VERSION "1.0.x-173216:1"

NS_ :

BS_:

BU_: PropulsionBatteryCharger iBooster TCM HCU STEERING_CONTROLLER BMS Traction_Motor_Controller

BO_ 2565865739 EBC1_11: 8 Vector__XXX
 SG_ ABSActive : 4|2@1+ (1,0) [0|3] "" Vector__XXX
 SG_ ASREngineCtrlActive : 0|2@1+ (1,0) [0|3] "" Vector__XXX
 SG_ ASRBrakeCtrlActive : 2|2@1+ (1,0) [0|3] "" Vector__XXX
 SG_ BrakePedalPosition : 8|8@1+ (0.4,0) [0|100] "%" Vector__XXX
 SG_ ABSOffroadSwitch : 16|2@1+ (1,0) [0|3] "" Vector__XXX
 SG_ ASROffroadSwitch : 18|2@1+ (1,0) [0|3] "" Vector__XXX
 SG_ ASRHillHolderSwitch : 20|2@1+ (1,0) [0|3] "" Vector__XXX
 SG_ EBSBrakeSwitch : 6|2@1+ (1,0) [0|3] "" Vector__XXX
 SG_ DL17_TractionCtrlOverrideSwitch : 22|2@1+ (1,0) [0|0] "" Vector__XXX
 SG_ AcceleratorInterlockSwitch : 24|2@1+ (1,0) [0|3] "" Vector__XXX
 SG_ EngineDerateSwitch : 26|2@1+ (1,0) [0|3] "" Vector__XXX
 SG_ AuxEngineShutdownSwitch : 28|2@1+ (1,0) [0|3] "" Vector__XXX
 SG_ RemoteAcceleratorSwitch : 30|2@1+ (1,0) [0|3] "" Vector__XXX
 SG_ EngineRetarderSelection : 32|8@1+ (0.4,0) [0|100] "%" Vector__XXX
 SG_ ABSFullyOperational : 40|2@1+ (1,0) [0|3] "" Vector__XXX
 SG_ EBSRedWarningState : 42|2@1+ (1,0) [0|3] "" Vector__XXX
 SG_ ABSEBSAmberWarningState : 44|2@1+ (1,0) [0|3] "" Vector__XXX
 SG_ SourceAddress : 48|8@1+ (1,0) [0|253] "" Vector__XXX
 SG_ ATC_ASR_InfoSig : 46|2@1+ (1,0) [0|3] "" Vector__XXX

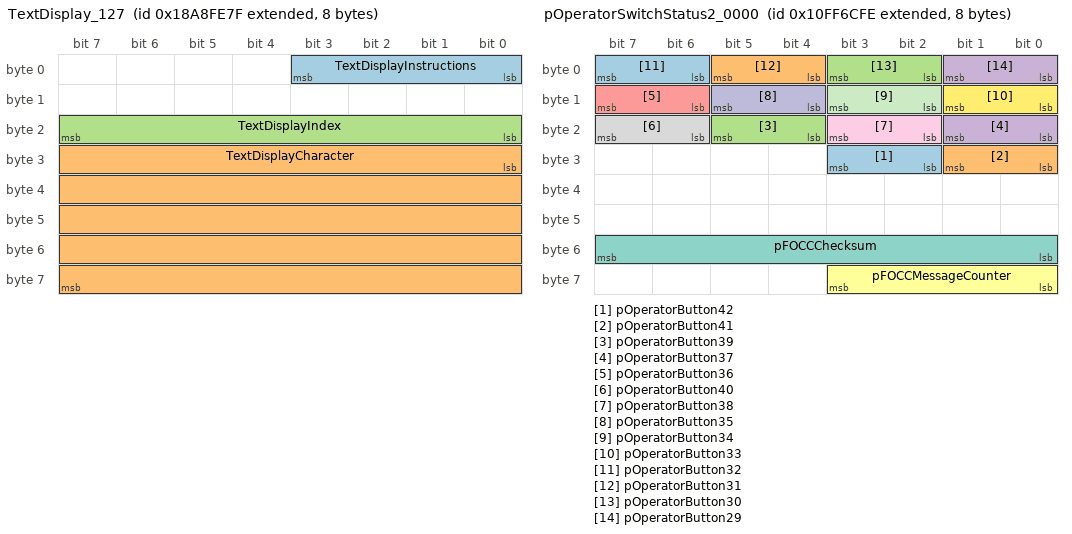
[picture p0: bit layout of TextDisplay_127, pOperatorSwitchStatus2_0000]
BO_ 2561212031 TextDisplay_127: 8 Vector__XXX
 SG_ TextDisplayInstructions : 0|4@1+ (1,0) [0|15] "" Vector__XXX
 SG_ TextDisplayCharacter : 24|40@1+ (1,0) [0|1099511627800] "ASCII" Vector__XXX
 SG_ TextDisplayIndex : 16|8@1+ (1,0) [0|250] "Count" Vector__XXX

BO_ 2432658686 pOperatorSwitchStatus2_0000: 8 Vector__XXX
 SG_ pOperatorButton42 : 26|2@1+ (1,0) [0|3] "" Vector__XXX
 SG_ pOperatorButton41 : 24|2@1+ (1,0) [0|3] "" Vector__XXX
 SG_ pOperatorButton39 : 20|2@1+ (1,0) [0|3] "" Vector__XXX
 SG_ pOperatorButton37 : 16|2@1+ (1,0) [0|3] "" Vector__XXX
 SG_ pOperatorButton36 : 14|2@1+ (1,0) [0|3] "" Vector__XXX
 SG_ pFOCCMessageCounter : 56|4@1+ (1,0) [0|15] "" Vector__XXX
 SG_ pFOCCChecksum : 48|8@1+ (1,0) [0|255] "" Vector__XXX
 SG_ pOperatorButton40 : 22|2@1+ (1,0) [0|3] "" Vector__XXX
 SG_ pOperatorButton38 : 18|2@1+ (1,0) [0|3] "" Vector__XXX
 SG_ pOperatorButton35 : 12|2@1+ (1,0) [0|3] "" Vector__XXX
 SG_ pOperatorButton34 : 10|2@1+ (1,0) [0|3] "" Vector__XXX
 SG_ pOperatorButton33 : 8|2@1+ (1,0) [0|3] "" Vector__XXX
 SG_ pOperatorButton32 : 6|2@1+ (1,0) [0|3] "" Vector__XXX
 SG_ pOperatorButton31 : 4|2@1+ (1,0) [0|3] "" Vector__XXX
 SG_ pOperatorButton30 : 2|2@1+ (1,0) [0|3] "" Vector__XXX
 SG_ pOperatorButton29 : 0|2@1+ (1,0) [0|3] "" Vector__XXX

BO_ 2633984766 pDriveSystemStatus_0: 8 Vector__XXX
 SG_ pHeatedGripEnable : 48|2@1+ (1,0) [0|3] "" Vector__XXX
 SG_ pSideStandStatus : 36|2@1+ (1,0) [0|3] "" Vector__XXX
 SG_ pTetherSwitchStatus : 46|2@1+ (1,0) [0|3] "" Vector__XXX
 SG_ pLowFuelIndicatorStatus : 10|2@1+ (1,0) [0|3] "" Vector__XXX
 SG_ pOperatorNotInOperatingStation : 38|2@1+ (1,0) [0|3] "" Vector__XXX
 SG_ pParkBrakeIndicatorStatus : 40|3@1+ (1,0) [0|7] "" Vector__XXX
 SG_ pADCRequested : 34|2@1+ (1,0) [0|3] "" Vector__XXX
 SG_ pAWDModeRequested : 32|2@1+ (1,0) [0|3] "" Vector__XXX
 SG_ pRWDModeRequested : 30|2@1+ (1,0) [0|3] "" Vector__XXX
 SG_ pTurfModeRequested : 28|2@1+ (1,0) [0|3] "" Vector__XXX
 SG_ pADCStatus : 0|2@1+ (1,0) [0|3] "" Vector__XXX
 SG_ pTreadleNeutralStatus : 2|2@1+ (1,0) [0|3] "" Vector__XXX
 SG_ pTreadleReverseStatus : 4|2@1+ (1,0) [0|3] "" Vector__XXX
 SG_ pSecurityLightStatus : 6|2@1+ (1,0) [0|3] "" Vector__XXX
 SG_ pHighBeamIndicatorStatus : 8|2@1+ (1,0) [0|3] "" Vector__XXX
 SG_ pHeatedGripsPercentage : 16|8@1+ (0.4,0) [0|100] "%" Vector__XXX
 SG_ pCruiseControlSetStatus : 24|2@1+ (1,0) [0|3] "" Vector__XXX
 SG_ pSeatBeltIndicatorStatus : 12|3@1+ (1,0) [0|7] "" Vector__XXX

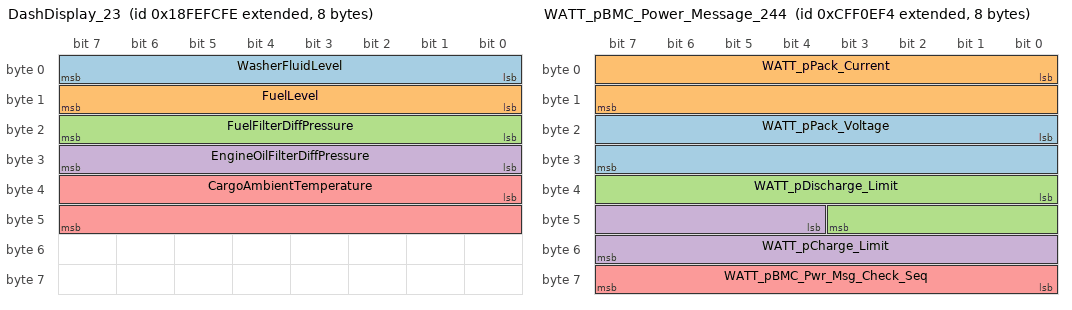
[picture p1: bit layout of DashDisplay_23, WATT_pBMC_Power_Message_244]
BO_ 2566847742 DashDisplay_23: 8 Vector__XXX
 SG_ WasherFluidLevel : 0|8@1+ (0.4,0) [0|100] "%" Vector__XXX
 SG_ FuelLevel : 8|8@1+ (0.4,0) [0|100] "%" Vector__XXX
 SG_ FuelFilterDiffPressure : 16|8@1+ (2,0) [0|500] "kPa" Vector__XXX
 SG_ EngineOilFilterDiffPressure : 24|8@1+ (0.5,0) [0|125] "kPa" Vector__XXX
 SG_ CargoAmbientTemperature : 32|16@1+ (0.03125,-273) [-273|1735] "°C" Vector__XXX

BO_ 2566832638 HiResVehicleDist_23: 8 Vector__XXX
 SG_ HighResolTotalVehicleDistance : 0|32@1+ (0.005,0) [0|21055406] "km" Vector__XXX
 SG_ HighResolTripDistance : 32|32@1+ (0.005,0) [0|21055406] "km" Vector__XXX

BO_ 2432656640 pOperatorSwitchStatus_0: 8 Vector__XXX
 SG_ pOperatorButton29 : 58|2@1+ (1,0) [0|3] "" Vector__XXX
 SG_ pOperatorButton1 : 0|2@1+ (1,0) [0|3] "" Vector__XXX
 SG_ pOperatorButton2 : 2|2@1+ (1,0) [0|3] "" Vector__XXX
 SG_ pOperatorButton3 : 4|2@1+ (1,0) [0|3] "" Vector__XXX
 SG_ pOperatorButton4 : 6|2@1+ (1,0) [0|3] "" Vector__XXX
 SG_ pOperatorButton5 : 8|2@1+ (1,0) [0|3] "" Vector__XXX
 SG_ pOperatorButton6 : 10|2@1+ (1,0) [0|3] "" Vector__XXX
 SG_ pOperatorButton7 : 12|2@1+ (1,0) [0|3] "" Vector__XXX
 SG_ pOperatorButton8 : 14|2@1+ (1,0) [0|3] "" Vector__XXX
 SG_ pOperatorButton9 : 16|2@1+ (1,0) [0|3] "" Vector__XXX
 SG_ pOperatorButton10 : 18|2@1+ (1,0) [0|3] "" Vector__XXX
 SG_ pOperatorButton11 : 20|2@1+ (1,0) [0|3] "" Vector__XXX
 SG_ pOperatorButton12 : 22|2@1+ (1,0) [0|3] "" Vector__XXX
 SG_ pOperatorButton13 : 24|2@1+ (1,0) [0|3] "" Vector__XXX
 SG_ pOperatorButton14 : 26|2@1+ (1,0) [0|3] "" Vector__XXX
 SG_ pOperatorButton15 : 28|2@1+ (1,0) [0|3] "" Vector__XXX
 SG_ pOperatorButton16 : 30|2@1+ (1,0) [0|3] "" Vector__XXX
 SG_ pOperatorButton17 : 32|2@1+ (1,0) [0|3] "" Vector__XXX
 SG_ pOperatorButton18 : 34|2@1+ (1,0) [0|3] "" Vector__XXX
 SG_ pOperatorButton19 : 36|2@1+ (1,0) [0|3] "" Vector__XXX
 SG_ pOperatorButton20 : 38|2@1+ (1,0) [0|3] "" Vector__XXX
 SG_ pOperatorButton21 : 40|2@1+ (1,0) [0|3] "" Vector__XXX
 SG_ pOperatorButton22 : 42|2@1+ (1,0) [0|3] "" Vector__XXX
 SG_ pOperatorButton23 : 44|2@1+ (1,0) [0|3] "" Vector__XXX
 SG_ pOperatorButton24 : 46|2@1+ (1,0) [0|3] "" Vector__XXX
 SG_ pOperatorButton25 : 48|2@1+ (1,0) [0|3] "" Vector__XXX
 SG_ pOperatorButton26 : 50|2@1+ (1,0) [0|3] "" Vector__XXX
 SG_ pOperatorButton27 : 52|2@1+ (1,0) [0|3] "" Vector__XXX
 SG_ pOperatorButton28 : 54|2@1+ (1,0) [0|3] "" Vector__XXX
 SG_ pSideStandStatus : 56|2@1+ (1,0) [0|3] "" Vector__XXX

BO_ 2566804212 VehicleElectricalPower3_244: 8 Vector__XXX
 SG_ NetBattCurrentHiRange : 16|16@1+ (0.05,0) [0|3276.75] "A" Vector__XXX

BO_ 2566804211 VehicleElectricalPower3_243: 8 BMS
 SG_ NetBattCurrentHiRange : 16|16@1+ (0.05,0) [0|3276.75] "A" Vector__XXX

BO_ 2365525748 WATT_pBMC_Power_Message_244: 8 Vector__XXX
 SG_ WATT_pPack_Voltage : 16|16@1+ (0.05,0) [0|3212.75] "V" Vector__XXX
 SG_ WATT_pPack_Current : 0|16@1+ (0.05,-1600) [-1600|1612.75] "A" Vector__XXX
 SG_ WATT_pDischarge_Limit : 32|12@1+ (0.5,0) [0|2007.5] "A" Vector__XXX
 SG_ WATT_pCharge_Limit : 44|12@1+ (0.5,0) [0|2007.5] "A" Vector__XXX
 SG_ WATT_pBMC_Pwr_Msg_Check_Seq : 56|8@1+ (1,0) [0|255] "" Vector__XXX

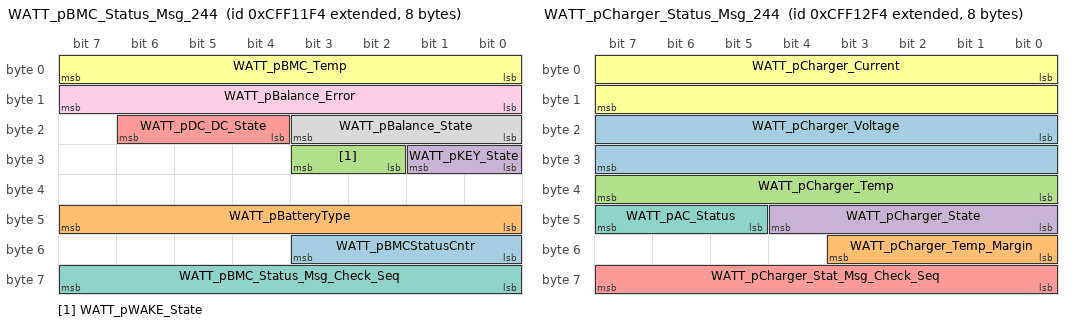
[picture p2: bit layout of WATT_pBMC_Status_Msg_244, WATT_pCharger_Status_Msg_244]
BO_ 2365526516 WATT_pBMC_Status_Msg_244: 8 Vector__XXX
 SG_ WATT_pBMCStatusCntr : 48|4@1+ (1,0) [0|15] "" Vector__XXX
 SG_ WATT_pBatteryType : 40|8@1+ (1,0) [0|255] "" Vector__XXX
 SG_ WATT_pWAKE_State : 26|2@1+ (1,0) [0|3] "" Vector__XXX
 SG_ WATT_pKEY_State : 24|2@1+ (1,0) [0|3] "" Vector__XXX
 SG_ WATT_pDC_DC_State : 20|3@1+ (1,0) [0|7] "" Vector__XXX
 SG_ WATT_pBMC_Temp : 0|8@1+ (1,-40) [-40|200] "C" Vector__XXX
 SG_ WATT_pBMC_Status_Msg_Check_Seq : 56|8@1+ (1,0) [0|255] "" Vector__XXX
 SG_ WATT_pBalance_State : 16|4@1+ (1,0) [0|15] "" Vector__XXX
 SG_ WATT_pBalance_Error : 8|8@1+ (0.5,-6.4) [-6.4|6.1] "%" Vector__XXX

BO_ 2365526772 WATT_pCharger_Status_Msg_244: 8 Vector__XXX
 SG_ WATT_pCharger_Voltage : 16|16@1+ (0.05,0) [0|3212.75] "V" Vector__XXX
 SG_ WATT_pCharger_Temp_Margin : 48|4@1+ (1,0) [0|15] "" Vector__XXX
 SG_ WATT_pCharger_Temp : 32|8@1+ (1,-40) [-40|200] "C" Vector__XXX
 SG_ WATT_pCharger_State : 40|5@1+ (1,0) [0|31] "" Vector__XXX
 SG_ WATT_pCharger_Stat_Msg_Check_Seq : 56|8@1+ (1,0) [0|255] "" Vector__XXX
 SG_ WATT_pCharger_Current : 0|16@1+ (0.05,-1600) [-1600|1612.75] "A" Vector__XXX
 SG_ WATT_pAC_Status : 45|3@1+ (1,0) [0|7] "" Vector__XXX

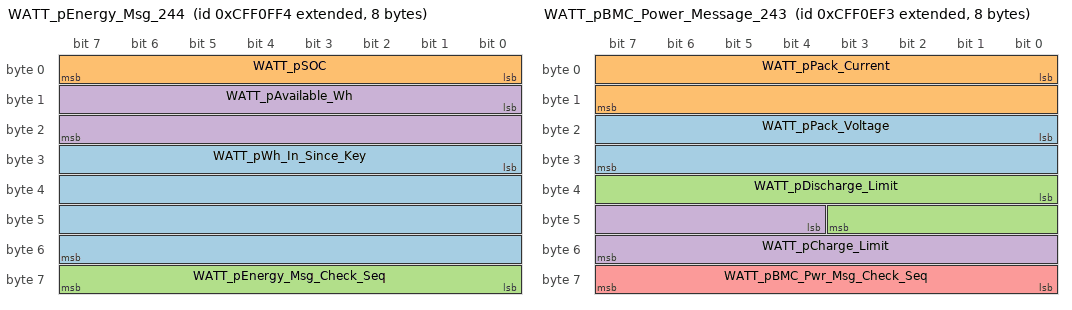
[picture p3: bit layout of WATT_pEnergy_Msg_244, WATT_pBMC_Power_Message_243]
BO_ 2365526004 WATT_pEnergy_Msg_244: 8 Vector__XXX
 SG_ WATT_pWh_In_Since_Key : 24|32@1+ (6.10352E-005,-131072) [-131072|126000] "Wh" Vector__XXX
 SG_ WATT_pSOC : 0|8@1+ (0.5,0) [0|100] "%" Vector__XXX
 SG_ WATT_pEnergy_Msg_Check_Seq : 56|8@1+ (1,0) [0|255] "" Vector__XXX
 SG_ WATT_pAvailable_Wh : 8|16@1+ (4,0) [0|257020] "Wh" Vector__XXX

BO_ 2365525747 WATT_pBMC_Power_Message_243: 8 BMS
 SG_ WATT_pPack_Voltage : 16|16@1+ (0.05,0) [0|3212.75] "V" Vector__XXX
 SG_ WATT_pPack_Current : 0|16@1+ (0.05,-1600) [-1600|1612.75] "A" Vector__XXX
 SG_ WATT_pDischarge_Limit : 32|12@1+ (0.5,0) [0|2007.5] "A" Vector__XXX
 SG_ WATT_pCharge_Limit : 44|12@1+ (0.5,0) [0|2007.5] "A" Vector__XXX
 SG_ WATT_pBMC_Pwr_Msg_Check_Seq : 56|8@1+ (1,0) [0|255] "" Vector__XXX

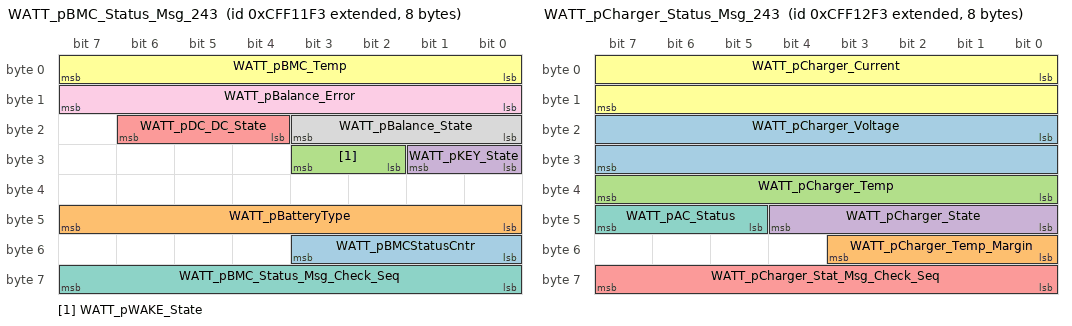
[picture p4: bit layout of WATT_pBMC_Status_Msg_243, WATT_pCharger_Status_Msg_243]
BO_ 2365526515 WATT_pBMC_Status_Msg_243: 8 BMS
 SG_ WATT_pBMCStatusCntr : 48|4@1+ (1,0) [0|15] "" Vector__XXX
 SG_ WATT_pBatteryType : 40|8@1+ (1,0) [0|255] "" Vector__XXX
 SG_ WATT_pWAKE_State : 26|2@1+ (1,0) [0|3] "" Vector__XXX
 SG_ WATT_pKEY_State : 24|2@1+ (1,0) [0|3] "" Vector__XXX
 SG_ WATT_pDC_DC_State : 20|3@1+ (1,0) [0|7] "" Vector__XXX
 SG_ WATT_pBMC_Temp : 0|8@1+ (1,-40) [-40|200] "C" Vector__XXX
 SG_ WATT_pBMC_Status_Msg_Check_Seq : 56|8@1+ (1,0) [0|255] "" Vector__XXX
 SG_ WATT_pBalance_State : 16|4@1+ (1,0) [0|15] "" Vector__XXX
 SG_ WATT_pBalance_Error : 8|8@1+ (0.5,-6.4) [-6.4|6.1] "%" Vector__XXX

BO_ 2365526771 WATT_pCharger_Status_Msg_243: 8 BMS
 SG_ WATT_pCharger_Voltage : 16|16@1+ (0.05,0) [0|3212.75] "V" Vector__XXX
 SG_ WATT_pCharger_Temp_Margin : 48|4@1+ (1,0) [0|15] "" Vector__XXX
 SG_ WATT_pCharger_Temp : 32|8@1+ (1,-40) [-40|200] "C" Vector__XXX
 SG_ WATT_pCharger_State : 40|5@1+ (1,0) [0|31] "" Vector__XXX
 SG_ WATT_pCharger_Stat_Msg_Check_Seq : 56|8@1+ (1,0) [0|255] "" Vector__XXX
 SG_ WATT_pCharger_Current : 0|16@1+ (0.05,-1600) [-1600|1612.75] "A" Vector__XXX
 SG_ WATT_pAC_Status : 45|3@1+ (1,0) [0|7] "" Vector__XXX

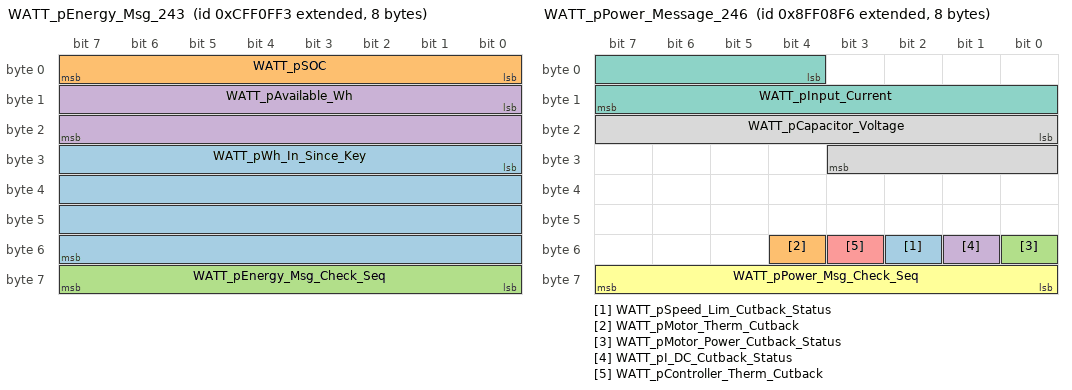
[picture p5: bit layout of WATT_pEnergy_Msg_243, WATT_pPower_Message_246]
BO_ 2365526003 WATT_pEnergy_Msg_243: 8 BMS
 SG_ WATT_pWh_In_Since_Key : 24|32@1+ (6.10352E-005,-131072) [-131072|126000] "Wh" Vector__XXX
 SG_ WATT_pSOC : 0|8@1+ (0.5,0) [0|100] "%" Vector__XXX
 SG_ WATT_pEnergy_Msg_Check_Seq : 56|8@1+ (1,0) [0|255] "" Vector__XXX
 SG_ WATT_pAvailable_Wh : 8|16@1+ (4,0) [0|257020] "Wh" Vector__XXX

BO_ 2298415094 WATT_pPerformance_Message_246: 8 Vector__XXX
 SG_ WATT_pUpper_Available_Torque : 16|8@1+ (2.5,-312.5) [-312.5|312.5] "Nm" Vector__XXX
 SG_ WATT_pPerformance_State : 0|4@1+ (1,0) [0|15] "" Vector__XXX
 SG_ WATT_pPerformance_Msg_Check_Seq : 56|8@1+ (1,0) [0|255] "" Vector__XXX
 SG_ WATT_pLower_Available_Torque : 28|8@1+ (2.5,-312.5) [-312.5|312.5] "Nm" Vector__XXX
 SG_ WATT_pActual_Motor_Velocity : 40|16@1+ (1,-32768) [-32768|31488] "RPM" Vector__XXX
 SG_ WATT_pActual_Motor_torque : 4|16@1+ (0.1,-3276.8) [-3276.8|3148.7] "Nm" Vector__XXX

BO_ 2298415350 WATT_pPower_Message_246: 8 Vector__XXX
 SG_ WATT_pSpeed_Lim_Cutback_Status : 50|1@1+ (1,0) [0|1] "" Vector__XXX
 SG_ WATT_pMotor_Therm_Cutback : 52|1@1+ (1,0) [0|1] "" Vector__XXX
 SG_ WATT_pMotor_Power_Cutback_Status : 48|1@1+ (1,0) [0|1] "" Vector__XXX
 SG_ WATT_pI_DC_Cutback_Status : 49|1@1+ (1,0) [0|1] "" Vector__XXX
 SG_ WATT_pController_Therm_Cutback : 51|1@1+ (1,0) [0|1] "" Vector__XXX
 SG_ WATT_pPower_Msg_Check_Seq : 56|8@1+ (1,0) [0|255] "" Vector__XXX
 SG_ WATT_pInput_Current : 4|12@1+ (1,0) [0|4095] "" Vector__XXX
 SG_ WATT_pCapacitor_Voltage : 16|12@1+ (1,0) [0|4095] "" Vector__XXX

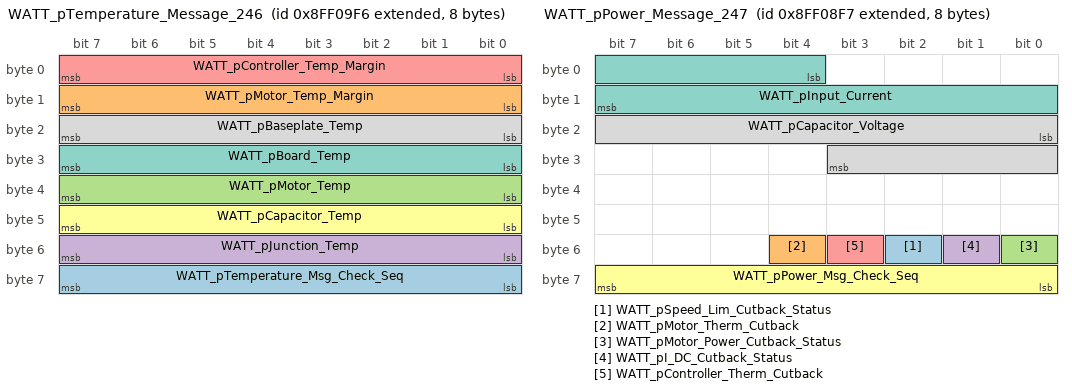
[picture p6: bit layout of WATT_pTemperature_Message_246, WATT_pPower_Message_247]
BO_ 2298415606 WATT_pTemperature_Message_246: 8 Vector__XXX
 SG_ WATT_pTemperature_Msg_Check_Seq : 56|8@1+ (1,0) [0|255] "" Vector__XXX
 SG_ WATT_pMotor_Temp_Margin : 8|8@1+ (1,0) [0|250] "C" Vector__XXX
 SG_ WATT_pMotor_Temp : 32|8@1+ (1,-40) [-40|210] "C" Vector__XXX
 SG_ WATT_pJunction_Temp : 48|8@1+ (1,-40) [-40|210] "C" Vector__XXX
 SG_ WATT_pController_Temp_Margin : 0|8@1+ (1,0) [0|250] "C" Vector__XXX
 SG_ WATT_pCapacitor_Temp : 40|8@1+ (1,-40) [-40|210] "C" Vector__XXX
 SG_ WATT_pBoard_Temp : 24|8@1+ (1,-40) [-40|210] "C" Vector__XXX
 SG_ WATT_pBaseplate_Temp : 16|8@1+ (1,-40) [-40|210] "C" Vector__XXX

BO_ 2298415095 WATT_pPerformance_Message_247: 8 Vector__XXX
 SG_ WATT_pUpper_Available_Torque : 16|8@1+ (2.5,-312.5) [-312.5|312.5] "Nm" Vector__XXX
 SG_ WATT_pPerformance_State : 0|4@1+ (1,0) [0|15] "" Vector__XXX
 SG_ WATT_pPerformance_Msg_Check_Seq : 56|8@1+ (1,0) [0|255] "" Vector__XXX
 SG_ WATT_pLower_Available_Torque : 28|8@1+ (2.5,-312.5) [-312.5|312.5] "Nm" Vector__XXX
 SG_ WATT_pActual_Motor_Velocity : 40|16@1+ (1,-32768) [-32768|31488] "RPM" Vector__XXX
 SG_ WATT_pActual_Motor_torque : 4|16@1+ (0.1,-3276.8) [-3276.8|3148.7] "Nm" Vector__XXX

BO_ 2298415351 WATT_pPower_Message_247: 8 Vector__XXX
 SG_ WATT_pSpeed_Lim_Cutback_Status : 50|1@1+ (1,0) [0|1] "" Vector__XXX
 SG_ WATT_pMotor_Therm_Cutback : 52|1@1+ (1,0) [0|1] "" Vector__XXX
 SG_ WATT_pMotor_Power_Cutback_Status : 48|1@1+ (1,0) [0|1] "" Vector__XXX
 SG_ WATT_pI_DC_Cutback_Status : 49|1@1+ (1,0) [0|1] "" Vector__XXX
 SG_ WATT_pController_Therm_Cutback : 51|1@1+ (1,0) [0|1] "" Vector__XXX
 SG_ WATT_pPower_Msg_Check_Seq : 56|8@1+ (1,0) [0|255] "" Vector__XXX
 SG_ WATT_pInput_Current : 4|12@1+ (1,0) [0|4095] "" Vector__XXX
 SG_ WATT_pCapacitor_Voltage : 16|12@1+ (1,0) [0|4095] "" Vector__XXX

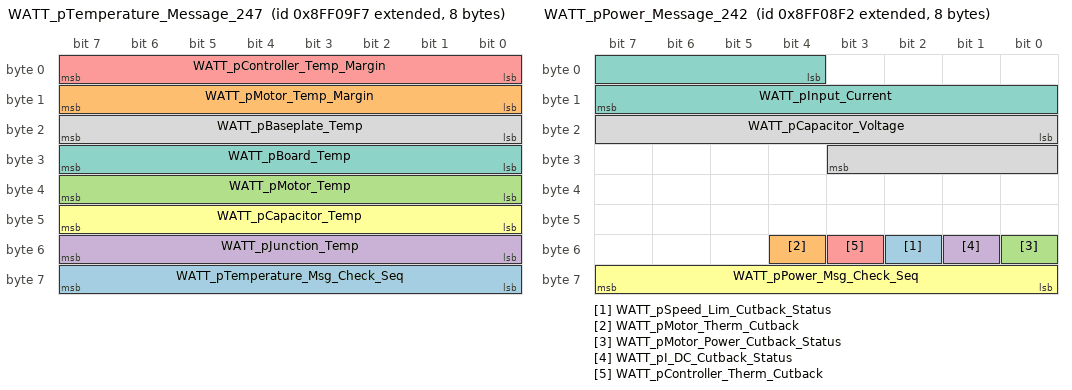
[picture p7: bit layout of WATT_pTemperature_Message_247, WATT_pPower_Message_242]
BO_ 2298415607 WATT_pTemperature_Message_247: 8 Vector__XXX
 SG_ WATT_pTemperature_Msg_Check_Seq : 56|8@1+ (1,0) [0|255] "" Vector__XXX
 SG_ WATT_pMotor_Temp_Margin : 8|8@1+ (1,0) [0|250] "C" Vector__XXX
 SG_ WATT_pMotor_Temp : 32|8@1+ (1,-40) [-40|210] "C" Vector__XXX
 SG_ WATT_pJunction_Temp : 48|8@1+ (1,-40) [-40|210] "C" Vector__XXX
 SG_ WATT_pController_Temp_Margin : 0|8@1+ (1,0) [0|250] "C" Vector__XXX
 SG_ WATT_pCapacitor_Temp : 40|8@1+ (1,-40) [-40|210] "C" Vector__XXX
 SG_ WATT_pBoard_Temp : 24|8@1+ (1,-40) [-40|210] "C" Vector__XXX
 SG_ WATT_pBaseplate_Temp : 16|8@1+ (1,-40) [-40|210] "C" Vector__XXX

BO_ 2298415090 WATT_pPerformance_Message_242: 8 Vector__XXX
 SG_ WATT_pUpper_Available_Torque : 16|8@1+ (2.5,-312.5) [-312.5|312.5] "Nm" Vector__XXX
 SG_ WATT_pPerformance_State : 0|4@1+ (1,0) [0|15] "" Vector__XXX
 SG_ WATT_pPerformance_Msg_Check_Seq : 56|8@1+ (1,0) [0|255] "" Vector__XXX
 SG_ WATT_pLower_Available_Torque : 28|8@1+ (2.5,-312.5) [-312.5|312.5] "Nm" Vector__XXX
 SG_ WATT_pActual_Motor_Velocity : 40|16@1+ (1,-32768) [-32768|31488] "RPM" Vector__XXX
 SG_ WATT_pActual_Motor_torque : 4|16@1+ (0.1,-3276.8) [-3276.8|3148.7] "Nm" Vector__XXX

BO_ 2298415346 WATT_pPower_Message_242: 8 Vector__XXX
 SG_ WATT_pSpeed_Lim_Cutback_Status : 50|1@1+ (1,0) [0|1] "" Vector__XXX
 SG_ WATT_pMotor_Therm_Cutback : 52|1@1+ (1,0) [0|1] "" Vector__XXX
 SG_ WATT_pMotor_Power_Cutback_Status : 48|1@1+ (1,0) [0|1] "" Vector__XXX
 SG_ WATT_pI_DC_Cutback_Status : 49|1@1+ (1,0) [0|1] "" Vector__XXX
 SG_ WATT_pController_Therm_Cutback : 51|1@1+ (1,0) [0|1] "" Vector__XXX
 SG_ WATT_pPower_Msg_Check_Seq : 56|8@1+ (1,0) [0|255] "" Vector__XXX
 SG_ WATT_pInput_Current : 4|12@1+ (1,0) [0|4095] "" Vector__XXX
 SG_ WATT_pCapacitor_Voltage : 16|12@1+ (1,0) [0|4095] "" Vector__XXX

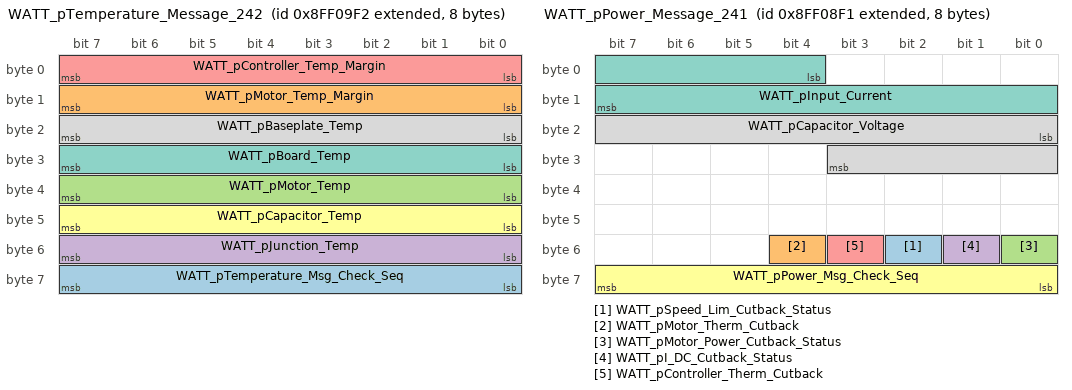
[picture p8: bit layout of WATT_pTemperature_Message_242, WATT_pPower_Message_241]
BO_ 2298415602 WATT_pTemperature_Message_242: 8 Vector__XXX
 SG_ WATT_pTemperature_Msg_Check_Seq : 56|8@1+ (1,0) [0|255] "" Vector__XXX
 SG_ WATT_pMotor_Temp_Margin : 8|8@1+ (1,0) [0|250] "C" Vector__XXX
 SG_ WATT_pMotor_Temp : 32|8@1+ (1,-40) [-40|210] "C" Vector__XXX
 SG_ WATT_pJunction_Temp : 48|8@1+ (1,-40) [-40|210] "C" Vector__XXX
 SG_ WATT_pController_Temp_Margin : 0|8@1+ (1,0) [0|250] "C" Vector__XXX
 SG_ WATT_pCapacitor_Temp : 40|8@1+ (1,-40) [-40|210] "C" Vector__XXX
 SG_ WATT_pBoard_Temp : 24|8@1+ (1,-40) [-40|210] "C" Vector__XXX
 SG_ WATT_pBaseplate_Temp : 16|8@1+ (1,-40) [-40|210] "C" Vector__XXX

BO_ 2298415089 WATT_pPerformance_Message_241: 8 Vector__XXX
 SG_ WATT_pUpper_Available_Torque : 16|8@1+ (2.5,-312.5) [-312.5|312.5] "Nm" Vector__XXX
 SG_ WATT_pPerformance_State : 0|4@1+ (1,0) [0|15] "" Vector__XXX
 SG_ WATT_pPerformance_Msg_Check_Seq : 56|8@1+ (1,0) [0|255] "" Vector__XXX
 SG_ WATT_pLower_Available_Torque : 28|8@1+ (2.5,-312.5) [-312.5|312.5] "Nm" Vector__XXX
 SG_ WATT_pActual_Motor_Velocity : 40|16@1+ (1,-32768) [-32768|31488] "RPM" Vector__XXX
 SG_ WATT_pActual_Motor_torque : 4|16@1+ (0.1,-3276.8) [-3276.8|3148.7] "Nm" Vector__XXX

BO_ 2298415345 WATT_pPower_Message_241: 8 Vector__XXX
 SG_ WATT_pSpeed_Lim_Cutback_Status : 50|1@1+ (1,0) [0|1] "" Vector__XXX
 SG_ WATT_pMotor_Therm_Cutback : 52|1@1+ (1,0) [0|1] "" Vector__XXX
 SG_ WATT_pMotor_Power_Cutback_Status : 48|1@1+ (1,0) [0|1] "" Vector__XXX
 SG_ WATT_pI_DC_Cutback_Status : 49|1@1+ (1,0) [0|1] "" Vector__XXX
 SG_ WATT_pController_Therm_Cutback : 51|1@1+ (1,0) [0|1] "" Vector__XXX
 SG_ WATT_pPower_Msg_Check_Seq : 56|8@1+ (1,0) [0|255] "" Vector__XXX
 SG_ WATT_pInput_Current : 4|12@1+ (1,0) [0|4095] "" Vector__XXX
 SG_ WATT_pCapacitor_Voltage : 16|12@1+ (1,0) [0|4095] "" Vector__XXX

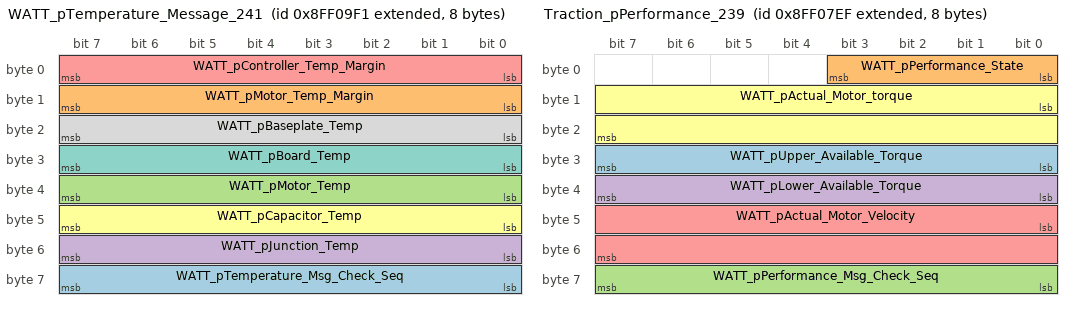
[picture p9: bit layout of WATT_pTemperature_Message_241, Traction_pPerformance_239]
BO_ 2298415601 WATT_pTemperature_Message_241: 8 Vector__XXX
 SG_ WATT_pTemperature_Msg_Check_Seq : 56|8@1+ (1,0) [0|255] "" Vector__XXX
 SG_ WATT_pMotor_Temp_Margin : 8|8@1+ (1,0) [0|250] "C" Vector__XXX
 SG_ WATT_pMotor_Temp : 32|8@1+ (1,-40) [-40|210] "C" Vector__XXX
 SG_ WATT_pJunction_Temp : 48|8@1+ (1,-40) [-40|210] "C" Vector__XXX
 SG_ WATT_pController_Temp_Margin : 0|8@1+ (1,0) [0|250] "C" Vector__XXX
 SG_ WATT_pCapacitor_Temp : 40|8@1+ (1,-40) [-40|210] "C" Vector__XXX
 SG_ WATT_pBoard_Temp : 24|8@1+ (1,-40) [-40|210] "C" Vector__XXX
 SG_ WATT_pBaseplate_Temp : 16|8@1+ (1,-40) [-40|210] "C" Vector__XXX

BO_ 2298415087 Traction_pPerformance_239: 8 Traction_Motor_Controller
 SG_ WATT_pUpper_Available_Torque : 24|8@1+ (2.5,-312.5) [-312.5|312.5] "Nm" Vector__XXX
 SG_ WATT_pPerformance_State : 0|4@1+ (1,0) [0|15] "" Vector__XXX
 SG_ WATT_pPerformance_Msg_Check_Seq : 56|8@1+ (1,0) [0|255] "" Vector__XXX
 SG_ WATT_pLower_Available_Torque : 32|8@1+ (2.5,-312.5) [-312.5|312.5] "Nm" Vector__XXX
 SG_ WATT_pActual_Motor_Velocity : 40|16@1+ (1,-32768) [-32768|31488] "RPM" Vector__XXX
 SG_ WATT_pActual_Motor_torque : 8|16@1+ (0.1,-3276.8) [-3276.8|3148.7] "Nm" Vector__XXX

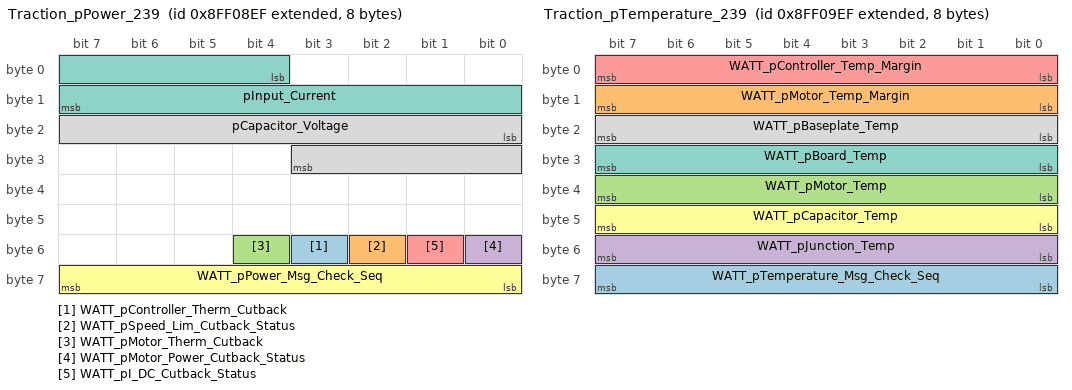
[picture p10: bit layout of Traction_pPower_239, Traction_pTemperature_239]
BO_ 2298415343 Traction_pPower_239: 8 Traction_Motor_Controller
 SG_ WATT_pController_Therm_Cutback : 51|1@1+ (1,0) [0|1] "" Vector__XXX
 SG_ WATT_pSpeed_Lim_Cutback_Status : 50|1@1+ (1,0) [0|1] "" Vector__XXX
 SG_ WATT_pMotor_Therm_Cutback : 52|1@1+ (1,0) [0|1] "" Vector__XXX
 SG_ WATT_pMotor_Power_Cutback_Status : 48|1@1+ (1,0) [0|1] "" Vector__XXX
 SG_ WATT_pI_DC_Cutback_Status : 49|1@1+ (1,0) [0|1] "" Vector__XXX
 SG_ WATT_pPower_Msg_Check_Seq : 56|8@1+ (1,0) [0|255] "" Vector__XXX
 SG_ pInput_Current : 4|12@1+ (0.341796875,-700) [-700|699.658203125] "A" Vector__XXX
 SG_ pCapacitor_Voltage : 16|12@1+ (0.0390625,0) [0|160] "V" Vector__XXX

BO_ 2298415599 Traction_pTemperature_239: 8 Traction_Motor_Controller
 SG_ WATT_pTemperature_Msg_Check_Seq : 56|8@1+ (1,0) [0|255] "" Vector__XXX
 SG_ WATT_pMotor_Temp_Margin : 8|8@1+ (1,0) [0|250] "C" Vector__XXX
 SG_ WATT_pMotor_Temp : 32|8@1+ (1,-40) [-40|210] "C" Vector__XXX
 SG_ WATT_pJunction_Temp : 48|8@1+ (1,-40) [-40|210] "C" Vector__XXX
 SG_ WATT_pController_Temp_Margin : 0|8@1+ (1,0) [0|250] "C" Vector__XXX
 SG_ WATT_pCapacitor_Temp : 40|8@1+ (1,-40) [-40|210] "C" Vector__XXX
 SG_ WATT_pBoard_Temp : 24|8@1+ (1,-40) [-40|210] "C" Vector__XXX
 SG_ WATT_pBaseplate_Temp : 16|8@1+ (1,-40) [-40|210] "C" Vector__XXX

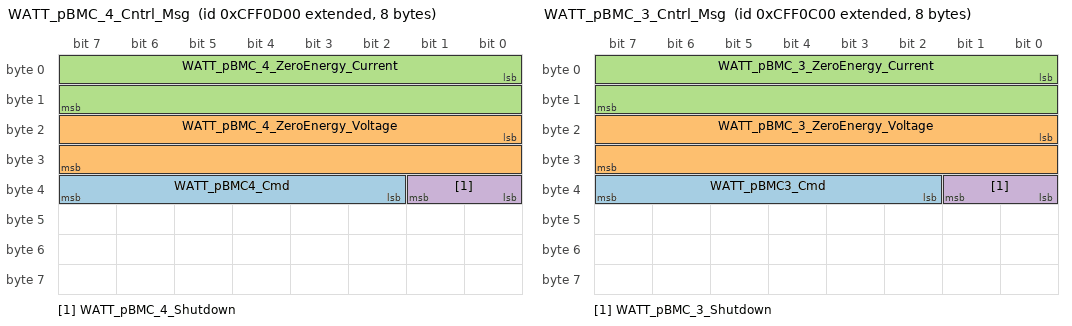
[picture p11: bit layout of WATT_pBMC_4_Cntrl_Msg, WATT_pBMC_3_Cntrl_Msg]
BO_ 2365525248 WATT_pBMC_4_Cntrl_Msg: 8 Vector__XXX
 SG_ WATT_pBMC4_Cmd : 34|6@1+ (1,0) [0|63] "" Vector__XXX
 SG_ WATT_pBMC_4_ZeroEnergy_Voltage : 16|16@1+ (0.05,0) [0|3212.75] "V" Vector__XXX
 SG_ WATT_pBMC_4_ZeroEnergy_Current : 0|16@1+ (0.05,-1600) [-1600|1612.75] "A" Vector__XXX
 SG_ WATT_pBMC_4_Shutdown : 32|2@1+ (1,0) [0|3] "" Vector__XXX

BO_ 2365524992 WATT_pBMC_3_Cntrl_Msg: 8 Vector__XXX
 SG_ WATT_pBMC3_Cmd : 34|6@1+ (1,0) [0|63] "" Vector__XXX
 SG_ WATT_pBMC_3_ZeroEnergy_Voltage : 16|16@1+ (0.05,0) [0|3212.75] "V" Vector__XXX
 SG_ WATT_pBMC_3_ZeroEnergy_Current : 0|16@1+ (0.05,-1600) [-1600|1612.75] "A" Vector__XXX
 SG_ WATT_pBMC_3_Shutdown : 32|2@1+ (1,0) [0|3] "" Vector__XXX

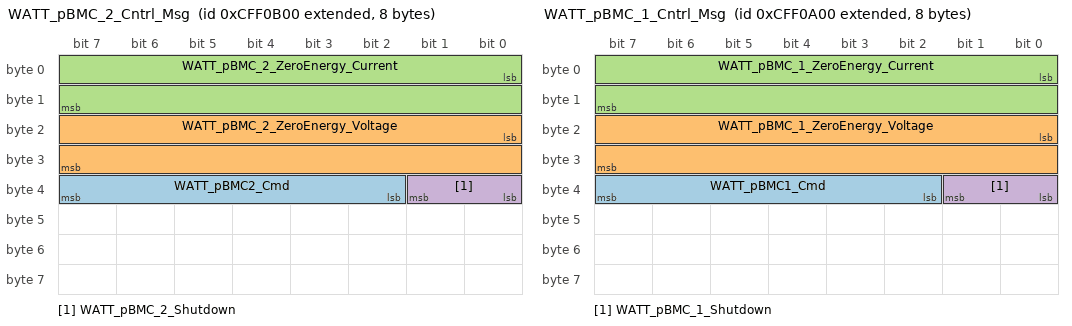
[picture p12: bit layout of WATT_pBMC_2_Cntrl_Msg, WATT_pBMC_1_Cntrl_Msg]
BO_ 2365524736 WATT_pBMC_2_Cntrl_Msg: 8 Vector__XXX
 SG_ WATT_pBMC2_Cmd : 34|6@1+ (1,0) [0|63] "" Vector__XXX
 SG_ WATT_pBMC_2_ZeroEnergy_Voltage : 16|16@1+ (0.05,0) [0|3212.75] "V" Vector__XXX
 SG_ WATT_pBMC_2_ZeroEnergy_Current : 0|16@1+ (0.05,-1600) [-1600|1612.75] "A" Vector__XXX
 SG_ WATT_pBMC_2_Shutdown : 32|2@1+ (1,0) [0|3] "" Vector__XXX

BO_ 2365524480 WATT_pBMC_1_Cntrl_Msg: 8 Vector__XXX
 SG_ WATT_pBMC1_Cmd : 34|6@1+ (1,0) [0|63] "" Vector__XXX
 SG_ WATT_pBMC_1_ZeroEnergy_Voltage : 16|16@1+ (0.05,0) [0|3212.75] "V" Vector__XXX
 SG_ WATT_pBMC_1_ZeroEnergy_Current : 0|16@1+ (0.05,-1600) [-1600|1612.75] "A" Vector__XXX
 SG_ WATT_pBMC_1_Shutdown : 32|2@1+ (1,0) [0|3] "" Vector__XXX

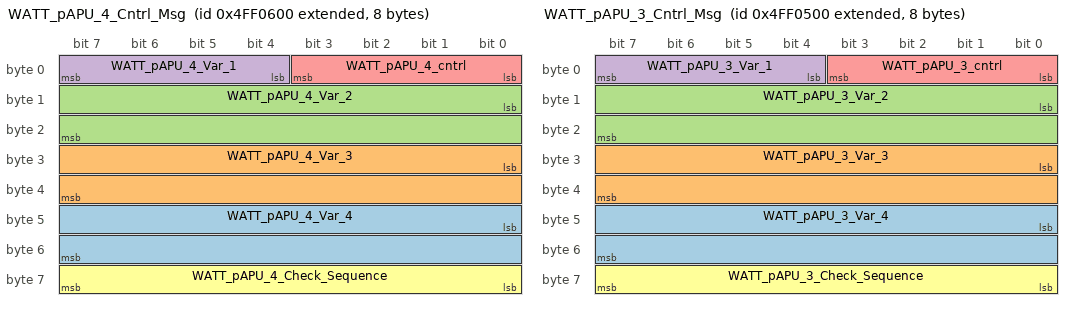
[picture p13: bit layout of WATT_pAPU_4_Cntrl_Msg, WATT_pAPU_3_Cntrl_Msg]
BO_ 2231305728 WATT_pAPU_4_Cntrl_Msg: 8 Vector__XXX
 SG_ WATT_pAPU_4_Var_4 : 40|16@1+ (1,-32768) [-32768|31488] "RPM" Vector__XXX
 SG_ WATT_pAPU_4_Var_3 : 24|16@1+ (0.1,-3276.8) [-3276.8|3148.7] "Nm" Vector__XXX
 SG_ WATT_pAPU_4_Var_2 : 8|16@1+ (0.1,-3276.8) [-3276.8|3148.7] "Nm" Vector__XXX
 SG_ WATT_pAPU_4_Var_1 : 4|4@1+ (1,0) [0|15] "" Vector__XXX
 SG_ WATT_pAPU_4_cntrl : 0|4@1+ (1,0) [0|15] "" Vector__XXX
 SG_ WATT_pAPU_4_Check_Sequence : 56|8@1+ (1,0) [0|255] "" Vector__XXX

BO_ 2231305472 WATT_pAPU_3_Cntrl_Msg: 8 Vector__XXX
 SG_ WATT_pAPU_3_Var_4 : 40|16@1+ (1,-32768) [-32768|31488] "RPM" Vector__XXX
 SG_ WATT_pAPU_3_Var_3 : 24|16@1+ (0.1,-3276.8) [-3276.8|3148.7] "Nm" Vector__XXX
 SG_ WATT_pAPU_3_Var_2 : 8|16@1+ (0.1,-3276.8) [-3276.8|3148.7] "Nm" Vector__XXX
 SG_ WATT_pAPU_3_Var_1 : 4|4@1+ (1,0) [0|15] "" Vector__XXX
 SG_ WATT_pAPU_3_cntrl : 0|4@1+ (1,0) [0|15] "" Vector__XXX
 SG_ WATT_pAPU_3_Check_Sequence : 56|8@1+ (1,0) [0|255] "" Vector__XXX

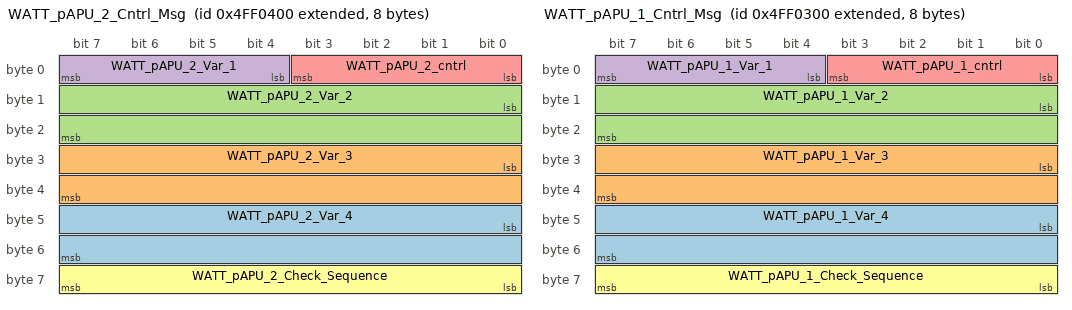
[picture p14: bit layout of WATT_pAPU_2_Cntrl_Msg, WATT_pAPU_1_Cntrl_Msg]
BO_ 2231305216 WATT_pAPU_2_Cntrl_Msg: 8 Vector__XXX
 SG_ WATT_pAPU_2_Var_4 : 40|16@1+ (1,-32768) [-32768|31488] "RPM" Vector__XXX
 SG_ WATT_pAPU_2_Var_3 : 24|16@1+ (0.1,-3276.8) [-3276.8|3148.7] "Nm" Vector__XXX
 SG_ WATT_pAPU_2_Var_2 : 8|16@1+ (0.1,-3276.8) [-3276.8|3148.7] "Nm" Vector__XXX
 SG_ WATT_pAPU_2_Var_1 : 4|4@1+ (1,0) [0|15] "" Vector__XXX
 SG_ WATT_pAPU_2_cntrl : 0|4@1+ (1,0) [0|15] "" Vector__XXX
 SG_ WATT_pAPU_2_Check_Sequence : 56|8@1+ (1,0) [0|255] "" Vector__XXX

BO_ 2231304960 WATT_pAPU_1_Cntrl_Msg: 8 Vector__XXX
 SG_ WATT_pAPU_1_Var_4 : 40|16@1+ (1,-32768) [-32768|31488] "RPM" Vector__XXX
 SG_ WATT_pAPU_1_Var_3 : 24|16@1+ (0.1,-3276.8) [-3276.8|3148.7] "Nm" Vector__XXX
 SG_ WATT_pAPU_1_Var_2 : 8|16@1+ (0.1,-3276.8) [-3276.8|3148.7] "Nm" Vector__XXX
 SG_ WATT_pAPU_1_Var_1 : 4|4@1+ (1,0) [0|15] "" Vector__XXX
 SG_ WATT_pAPU_1_cntrl : 0|4@1+ (1,0) [0|15] "" Vector__XXX
 SG_ WATT_pAPU_1_Check_Sequence : 56|8@1+ (1,0) [0|255] "" Vector__XXX

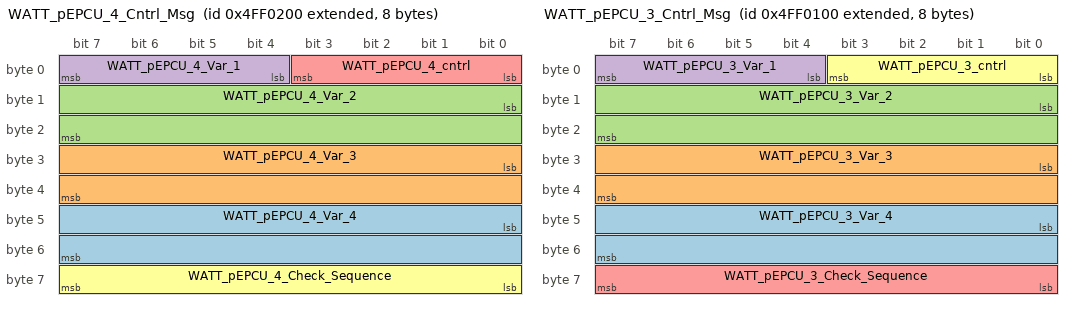
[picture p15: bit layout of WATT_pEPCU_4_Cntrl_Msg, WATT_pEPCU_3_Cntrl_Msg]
BO_ 2231304704 WATT_pEPCU_4_Cntrl_Msg: 8 Vector__XXX
 SG_ WATT_pEPCU_4_Var_4 : 40|16@1+ (1,-32768) [-32768|31488] "RPM" Vector__XXX
 SG_ WATT_pEPCU_4_Var_3 : 24|16@1+ (0.1,-3276.8) [-3276.8|3148.7] "Nm" Vector__XXX
 SG_ WATT_pEPCU_4_Var_2 : 8|16@1+ (0.1,-3276.8) [-3276.8|3148.7] "Nm" Vector__XXX
 SG_ WATT_pEPCU_4_Var_1 : 4|4@1+ (1,0) [0|15] "" Vector__XXX
 SG_ WATT_pEPCU_4_cntrl : 0|4@1+ (1,0) [0|15] "" Vector__XXX
 SG_ WATT_pEPCU_4_Check_Sequence : 56|8@1+ (1,0) [0|255] "" Vector__XXX

BO_ 2231304448 WATT_pEPCU_3_Cntrl_Msg: 8 Vector__XXX
 SG_ WATT_pEPCU_3_Var_4 : 40|16@1+ (1,-32768) [-32768|31488] "RPM" Vector__XXX
 SG_ WATT_pEPCU_3_Var_3 : 24|16@1+ (0.1,-3276.8) [-3276.8|3148.7] "Nm" Vector__XXX
 SG_ WATT_pEPCU_3_Var_2 : 8|16@1+ (0.1,-3276.8) [-3276.8|3148.7] "Nm" Vector__XXX
 SG_ WATT_pEPCU_3_Var_1 : 4|4@1+ (1,0) [0|15] "" Vector__XXX
 SG_ WATT_pEPCU_3_Check_Sequence : 56|8@1+ (1,0) [0|255] "" Vector__XXX
 SG_ WATT_pEPCU_3_cntrl : 0|4@1+ (1,0) [0|15] "" Vector__XXX

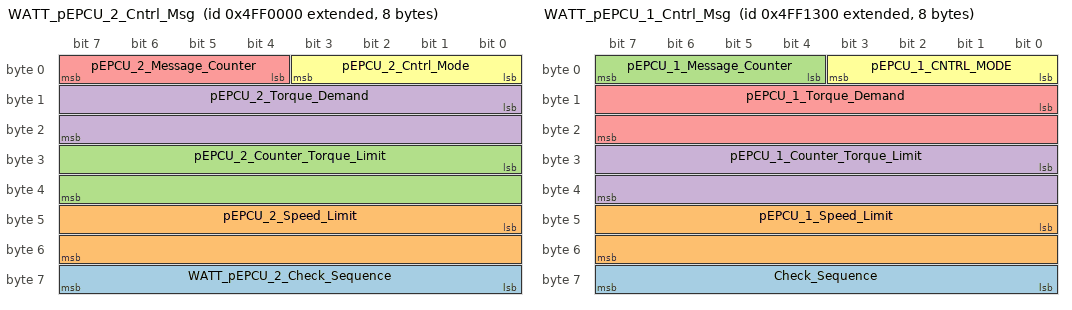
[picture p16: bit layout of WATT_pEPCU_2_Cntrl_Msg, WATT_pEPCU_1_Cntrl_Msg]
BO_ 2231304192 WATT_pEPCU_2_Cntrl_Msg: 8 Vector__XXX
 SG_ WATT_pEPCU_2_Check_Sequence : 56|8@1+ (1,0) [0|255] "" Vector__XXX
 SG_ pEPCU_2_Speed_Limit : 40|16@1+ (1,-32768) [-32768|32767] "RPM" Vector__XXX
 SG_ pEPCU_2_Counter_Torque_Limit : 24|16@1+ (0.1,-3276.8) [-3276.8|3148.7] "Nm" Vector__XXX
 SG_ pEPCU_2_Torque_Demand : 8|16@1+ (0.1,-3276.8) [-3276.8|3148.7] "Nm" Vector__XXX
 SG_ pEPCU_2_Message_Counter : 4|4@1+ (1,0) [0|15] "" Vector__XXX
 SG_ pEPCU_2_Cntrl_Mode : 0|4@1+ (1,0) [0|15] "" Vector__XXX

BO_ 2231309056 WATT_pEPCU_1_Cntrl_Msg: 8 Vector__XXX
 SG_ Check_Sequence : 56|8@1+ (1,0) [0|255] "" Vector__XXX
 SG_ pEPCU_1_Speed_Limit : 40|16@1+ (1,-32768) [-32768|31488] "RPM" Vector__XXX
 SG_ pEPCU_1_Message_Counter : 4|4@1+ (1,0) [0|15] "" Vector__XXX
 SG_ pEPCU_1_Counter_Torque_Limit : 24|16@1+ (0.1,-3276.8) [-3276.8|3148.7] "Nm" Vector__XXX
 SG_ pEPCU_1_Torque_Demand : 8|16@1+ (0.1,-3276.8) [-3276.8|3148.7] "Nm" Vector__XXX
 SG_ pEPCU_1_CNTRL_MODE : 0|4@1+ (1,0) [0|15] "" Vector__XXX

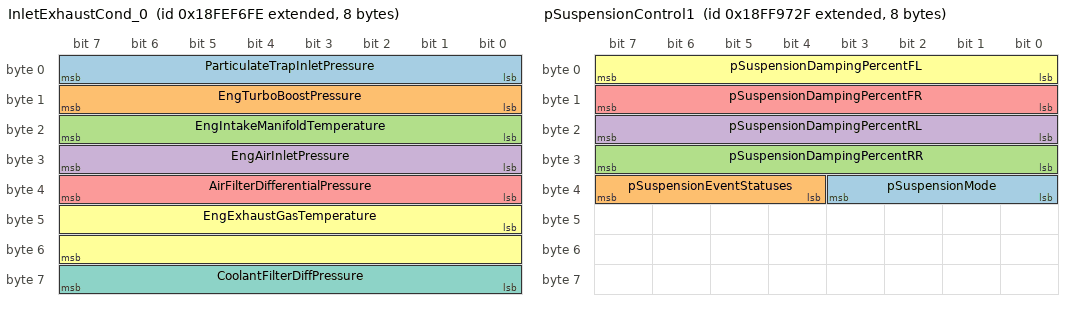
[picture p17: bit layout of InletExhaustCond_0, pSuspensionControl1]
BO_ 2566846206 InletExhaustCond_0: 8 Vector__XXX
 SG_ ParticulateTrapInletPressure : 0|8@1+ (0.5,0) [0|125] "kPa" Vector__XXX
 SG_ EngTurboBoostPressure : 8|8@1+ (2,0) [0|500] "kPa" Vector__XXX
 SG_ EngIntakeManifoldTemperature : 16|8@1+ (1,-40) [-40|210] "°C" Vector__XXX
 SG_ EngAirInletPressure : 24|8@1+ (2,0) [0|500] "kPa" Vector__XXX
 SG_ AirFilterDifferentialPressure : 32|8@1+ (0.05,0) [0|12.5] "kPa" Vector__XXX
 SG_ EngExhaustGasTemperature : 40|16@1+ (0.03125,-273) [-273|1734.96875] "°C" Vector__XXX
 SG_ CoolantFilterDiffPressure : 56|8@1+ (0.5,0) [0|125] "kPa" Vector__XXX

BO_ 2566887215 pSuspensionControl1: 8 Vector__XXX
 SG_ pSuspensionMode : 32|4@1+ (1,0) [0|15] "" Vector__XXX
 SG_ pSuspensionEventStatuses : 36|4@1+ (1,0) [0|15] "" Vector__XXX
 SG_ pSuspensionDampingPercentRR : 24|8@1+ (0.4,0) [0|100] "%" Vector__XXX
 SG_ pSuspensionDampingPercentRL : 16|8@1+ (0.4,0) [0|100] "%" Vector__XXX
 SG_ pSuspensionDampingPercentFR : 8|8@1+ (0.4,0) [0|100] "%" Vector__XXX
 SG_ pSuspensionDampingPercentFL : 0|8@1+ (0.4,0) [0|100] "%" Vector__XXX

BO_ 2566857470 pTSCF2: 8 Vector__XXX
 SG_ pNormalizedAcceleratorPosition : 8|16@1+ (0.1,0) [0|100] "%" Vector__XXX
 SG_ pRawBrakeSwitchStatus : 0|2@1+ (1,0) [0|3] "" Vector__XXX

CM_ BO_ 2565865739 "Electronic brake controller #1
Used for brake control information";
CM_ SG_ 2565865739 ABSActive "State signal which indicates that the ABS is active.  The signal is set when wheel brake pressure actually starts to be modulated by ABS and is reset when all wheels are in a stable condition
for a certain time.";
CM_ SG_ 2565865739 ASREngineCtrlActive "Not approved for use at Polaris at this time.

(State signal which indicates that ASR engine control has been commanded to be active)";
CM_ SG_ 2565865739 ASRBrakeCtrlActive "Not approved for use at Polaris at this time.

(State signal which indicates that ASR brake control is active)";
CM_ SG_ 2565865739 BrakePedalPosition "Not approved for use at Polaris at this time.";
CM_ SG_ 2565865739 ABSOffroadSwitch "Not approved for use at Polaris at this time.

(Switch signal which indicates the position of the ASR off-road switch)";
CM_ SG_ 2565865739 ASROffroadSwitch "Not approved for use at Polaris at this time.

(Switch signal which indicates the position of the ASR off-road switch)";
CM_ SG_ 2565865739 ASRHillHolderSwitch "Not approved for use at Polaris at this time.

(Switch signal which indicates the position of the ASR 'hill holder' switch)";
CM_ SG_ 2565865739 EBSBrakeSwitch "Not approved for use at Polaris at this time.

(Switch signal which indicates that the brake pedal is being pressed.)";
CM_ SG_ 2565865739 AcceleratorInterlockSwitch "Not approved for use at Polaris at this time.

(Switch signal used to disable the accelerator and remote accelerator input, causing the engine to return to idle.)";
CM_ SG_ 2565865739 EngineDerateSwitch "Not approved for use at Polaris at this time.

(Switch signal used to activate the torque limiting feature of the engine.)";
CM_ SG_ 2565865739 AuxEngineShutdownSwitch "Not approved for use at Polaris at this time.

(Switch signal which requests that all engine fueling stop.)";
CM_ SG_ 2565865739 RemoteAcceleratorSwitch "Not approved for use at Polaris at this time.

(Switch signal which indicates that the rmote accelerator has been enabled and controls the engine.)";
CM_ SG_ 2565865739 EngineRetarderSelection "Not approved for use at Polaris at this time.

(The percent engine retarder torque requested by the operator as percent of maximum braking torque at the current retarder speed.)";
CM_ SG_ 2565865739 ABSFullyOperational "Signal which indicates wether an ABS system is fully operational or wether its functionality is reduced by a defect or by an intended action.";
CM_ SG_ 2565865739 EBSRedWarningState "Not approved for use at Polaris at this time.

(The EBS red warning state is set if critical EBS faults are detected and the vehicle has to stop.)";
CM_ SG_ 2565865739 ABSEBSAmberWarningState "The ABS/EBS amber warning state is set as non-critical faults are detected in the ABS/EBS system.";
CM_ SG_ 2565865739 SourceAddress "Source address of controlling device for brake control.";
CM_ SG_ 2565865739 ATC_ASR_InfoSig "This parameter commands the ATC/ASR driver information signal, for example a dash lamp.  Used to control the amber traction control disabled lamp.";
CM_ BO_ 2561212031 "Text Display";
CM_ SG_ 2561212031 TextDisplayInstructions "This parameter describes the status for the display how to show the information.";
CM_ SG_ 2561212031 TextDisplayCharacter "From 1 up to 200 characters to be presented on a display. Up to 4 characters can be displayed without using Transport
Protocol.";
CM_ SG_ 2561212031 TextDisplayIndex "Used for overwriting consecutive bytes of a displayed string when byte 1 Text Display Instructions state is set for
overwrite substring mode.";
CM_ BO_ 2432658686 "Indicates the status of multiple operator controlled switches.";
CM_ SG_ 2432658686 pOperatorButton42 "Momentary Driveline Right Press";
CM_ SG_ 2432658686 pOperatorButton41 "Momentary Driveline Left Press";
CM_ SG_ 2432658686 pOperatorButton39 "Work Mode Switch Status";
CM_ SG_ 2432658686 pOperatorButton37 "Work Group Switch Status";
CM_ SG_ 2432658686 pOperatorButton36 "Tilt Lock Switch Status";
CM_ SG_ 2432658686 pFOCCMessageCounter "Rolling Counter (ensures updated message is used).";
CM_ SG_ 2432658686 pFOCCChecksum "XOR of bytes 0-6 (ensures data is valid before use). ";
CM_ SG_ 2432658686 pOperatorButton40 "Foot On Cruise Control Switch";
CM_ SG_ 2432658686 pOperatorButton38 "Operator Present Switch";
CM_ SG_ 2432658686 pOperatorButton35 "Driver's Net Engagement";
CM_ SG_ 2432658686 pOperatorButton34 "Driver's Seatbelt Engagement";
CM_ SG_ 2432658686 pOperatorButton33 "PTO Mode Switch (RPM control)";
CM_ SG_ 2432658686 pOperatorButton32 "Drive Mode - 4()";
CM_ SG_ 2432658686 pOperatorButton31 "Drive Mode - 3()";
CM_ SG_ 2432658686 pOperatorButton30 "Drive Mode - 2()";
CM_ SG_ 2432658686 pOperatorButton29 "Drive Mode - 1()";
CM_ BO_ 2633984766 "Status of Drive System Information";
CM_ SG_ 2633984766 pHeatedGripEnable "Indicates if the controller broadcasting this SPN is calibrated to support vehicle speed limit 3";
CM_ SG_ 2633984766 pSideStandStatus "Status of the side stand switch of a motorcycle";
CM_ SG_ 2633984766 pTetherSwitchStatus "Status of the Tether Switch";
CM_ SG_ 2633984766 pLowFuelIndicatorStatus "Broadcasting the status of the fuel level for user indication.";
CM_ SG_ 2633984766 pOperatorNotInOperatingStation "Status of Operator presence in a vehicle";
CM_ SG_ 2633984766 pParkBrakeIndicatorStatus "Broadcasting the status of the park brake for user indication";
CM_ SG_ 2633984766 pADCRequested "Broadcasting the status of the users request for ADC mode";
CM_ SG_ 2633984766 pAWDModeRequested "Broadcasting the status of the users request for AWD mode";
CM_ SG_ 2633984766 pRWDModeRequested "Broadcasting the status of the users request for RWD mode";
CM_ SG_ 2633984766 pTurfModeRequested "Broadcasting the status of the users request for TURF mode";
CM_ SG_ 2633984766 pADCStatus "Broadcasting the status of the ADC (active indicates the solenoid is powered)";
CM_ SG_ 2633984766 pTreadleNeutralStatus "Broadcasting the status of the switch indicating the treadle is/is not in the Neutral position";
CM_ SG_ 2633984766 pTreadleReverseStatus "Broadcasting the status of the switch indicating the treadle is/is not in the Reverse position";
CM_ SG_ 2633984766 pSecurityLightStatus "Broadcasting the status of the security system for user indication";
CM_ SG_ 2633984766 pHighBeamIndicatorStatus "Broadcasting the status of the high beam headlight for user indication";
CM_ SG_ 2633984766 pHeatedGripsPercentage "Heated Grips Percent On, 0% is Off and 100% is the maximum heat";
CM_ SG_ 2633984766 pCruiseControlSetStatus "Broadcasting the status of the Cruise Control Set Status for user indication";
CM_ SG_ 2633984766 pSeatBeltIndicatorStatus "Broadcasting the status of the seat belt for user indication";
CM_ SG_ 2566847742 WasherFluidLevel "Not approved for use at Polaris at this time.";
CM_ SG_ 2566847742 FuelLevel "Ratio of volume of fuel to the total volume of fuel storage container.";
CM_ SG_ 2566847742 FuelFilterDiffPressure "Not approved for use at Polaris at this time.";
CM_ SG_ 2566847742 EngineOilFilterDiffPressure "Not approved for use at Polaris at this time.";
CM_ SG_ 2566847742 CargoAmbientTemperature "Not approved for use at Polaris at this time.";
CM_ SG_ 2566832638 HighResolTotalVehicleDistance "Accumulated distance traveled by the vehicle during its operation";
CM_ SG_ 2566832638 HighResolTripDistance "Distance traveled during all or part of a journey";
CM_ BO_ 2432656640 "Indicates the status of multiple operator controlled switches.";
CM_ SG_ 2432656640 pOperatorButton29 "Drive Mode - 1()";
CM_ SG_ 2432656640 pOperatorButton1 "Instrument Cluster Control - 1";
CM_ SG_ 2432656640 pOperatorButton2 "Instrument Cluster Control  - 2";
CM_ SG_ 2432656640 pOperatorButton3 "Headlamp - 1 (Low)";
CM_ SG_ 2432656640 pOperatorButton4 "Headlamp - 2 (High)";
CM_ SG_ 2432656640 pOperatorButton5 "Headlamp - 3 (Driving)";
CM_ SG_ 2432656640 pOperatorButton6 "Turn - 1 (Left)";
CM_ SG_ 2432656640 pOperatorButton7 "Turn - 2 (Right)";
CM_ SG_ 2432656640 pOperatorButton8 "Turn - 3 (Cancel)";
CM_ SG_ 2432656640 pOperatorButton9 "Hazard";
CM_ SG_ 2432656640 pOperatorButton10 "Cruise - 1 (On)";
CM_ SG_ 2432656640 pOperatorButton11 "Cruise - 2 (Set)";
CM_ SG_ 2432656640 pOperatorButton12 "Cruise - 3 (Accel)";
CM_ SG_ 2432656640 pOperatorButton13 "Horn";
CM_ SG_ 2432656640 pOperatorButton14 "Start";
CM_ SG_ 2432656640 pOperatorButton15 "Warmer - 1";
CM_ SG_ 2432656640 pOperatorButton16 "Warmer - 2";
CM_ SG_ 2432656640 pOperatorButton17 "Warmer - 3";
CM_ SG_ 2432656640 pOperatorButton18 "Warmer - 4";
CM_ SG_ 2432656640 pOperatorButton19 "Windshield Wiper";
CM_ SG_ 2432656640 pOperatorButton20 "Engine On";
CM_ SG_ 2432656640 pOperatorButton21 "Reverse";
CM_ SG_ 2432656640 pOperatorButton22 "Suspension Adjust - 1 (Firm/Up)";
CM_ SG_ 2432656640 pOperatorButton23 "Suspension Adjust - 2 (Soft/Down)";
CM_ SG_ 2432656640 pOperatorButton24 "Throttle Safety Switch - 1";
CM_ SG_ 2432656640 pOperatorButton25 "Windshield - 1 (Up)";
CM_ SG_ 2432656640 pOperatorButton26 "Windshield - 2 (Down)";
CM_ SG_ 2432656640 pOperatorButton27 "Hand Brake Switch";
CM_ SG_ 2432656640 pOperatorButton28 "Clutch Switch";
CM_ SG_ 2432656640 pSideStandStatus "Status of the side stand switch of a motorcycle";
CM_ BO_ 2566804212 "This contains high resolution/range parameters reported from the alternator or power generation components.";
CM_ SG_ 2566804212 NetBattCurrentHiRange "Net flow of electrical current into/out-of the battery or batteries.";
CM_ BO_ 2566804211 "This contains high resolution/range parameters reported from the alternator or power generation components.";
CM_ SG_ 2566804211 NetBattCurrentHiRange "Net flow of electrical current into/out-of the battery or batteries.";
CM_ BO_ 2365525748 "BMC Power Information";
CM_ SG_ 2365525748 WATT_pPack_Voltage "The voltage of the battery pack monitored by the Battery Management Controller (BMC).";
CM_ SG_ 2365525748 WATT_pPack_Current "The current of the battery pack monitored by the Battery Management Controller (BMC).";
CM_ SG_ 2365525748 WATT_pDischarge_Limit "The discharge limit of the battery pack monitored by the Battery Management Controller (BMC).";
CM_ SG_ 2365525748 WATT_pCharge_Limit "The Charge limit of the battery pack monitored by the Battery Management Controller (BMC).";
CM_ SG_ 2365525748 WATT_pBMC_Pwr_Msg_Check_Seq "Checksum ensures data is valid before use.";
CM_ BO_ 2365526516 "BMC Status Information";
CM_ SG_ 2365526516 WATT_pWAKE_State "The state of the BMCÿs WAKE input.";
CM_ SG_ 2365526516 WATT_pKEY_State "State signifying the presence of an activated Key switch.";
CM_ SG_ 2365526516 WATT_pDC_DC_State "Operating state of the DC-DC converter controlled by the Battery Management Controller (BMC).";
CM_ SG_ 2365526516 WATT_pBMC_Temp "The temperature of the Battery Management Controller (BMC).";
CM_ SG_ 2365526516 WATT_pBMC_Status_Msg_Check_Seq "Checksum ensures data is valid before use.";
CM_ SG_ 2365526516 WATT_pBalance_State "The state of the BMC in terms of balancing the state of charge of the bottom battery and the top battery.";
CM_ SG_ 2365526516 WATT_pBalance_Error "The error in state of charge existing between the bottom battery and the top battery balanced by the Battery Management Controller (BMC). Positive error corresponds to the lower battery being at a higher state of charge.";
CM_ BO_ 2365526772 "Battery Charger Status Information";
CM_ SG_ 2365526772 WATT_pCharger_Voltage "The voltage output of the battery charger.";
CM_ SG_ 2365526772 WATT_pCharger_Temp_Margin "The smallest difference between an internal battery charger component and its thermal limit.";
CM_ SG_ 2365526772 WATT_pCharger_Temp "The temperature of the battery charger.";
CM_ SG_ 2365526772 WATT_pCharger_State "State of the battery charging process.";
CM_ SG_ 2365526772 WATT_pCharger_Stat_Msg_Check_Seq "Checksum ensures data is valid before use.";
CM_ SG_ 2365526772 WATT_pCharger_Current "The output current of the battery charger.";
CM_ SG_ 2365526772 WATT_pAC_Status "State signifying the presence of an AC Supply on the battery charger.";
CM_ BO_ 2365526004 "Vehicle Energy Information";
CM_ SG_ 2365526004 WATT_pWh_In_Since_Key "The capacity in Watt hours delivered to the battery pack monitored by the Battery Management Controller (BMC), negative for net energy removed from the battery pack.";
CM_ SG_ 2365526004 WATT_pSOC "The State of Charge (SOC) ÿ percent of battery capacity available at current battery health and temperature ÿ of the battery pack monitored by the Battery Management Controller (BMC).";
CM_ SG_ 2365526004 WATT_pEnergy_Msg_Check_Seq "Checksum ensures data is valid before use.";
CM_ SG_ 2365526004 WATT_pAvailable_Wh "The capacity, in Watt hours, of the battery pack monitored by the Battery Management Controller (BMC).";
CM_ BO_ 2365525747 "BMC Power Information";
CM_ SG_ 2365525747 WATT_pPack_Voltage "The voltage of the battery pack monitored by the Battery Management Controller (BMC).";
CM_ SG_ 2365525747 WATT_pPack_Current "The current of the battery pack monitored by the Battery Management Controller (BMC).";
CM_ SG_ 2365525747 WATT_pDischarge_Limit "The discharge limit of the battery pack monitored by the Battery Management Controller (BMC).";
CM_ SG_ 2365525747 WATT_pCharge_Limit "The Charge limit of the battery pack monitored by the Battery Management Controller (BMC).";
CM_ SG_ 2365525747 WATT_pBMC_Pwr_Msg_Check_Seq "Checksum ensures data is valid before use.";
CM_ BO_ 2365526515 "BMC Status Information";
CM_ SG_ 2365526515 WATT_pWAKE_State "The state of the BMCÿs WAKE input.";
CM_ SG_ 2365526515 WATT_pKEY_State "State signifying the presence of an activated Key switch.";
CM_ SG_ 2365526515 WATT_pDC_DC_State "Operating state of the DC-DC converter controlled by the Battery Management Controller (BMC).";
CM_ SG_ 2365526515 WATT_pBMC_Temp "The temperature of the Battery Management Controller (BMC).";
CM_ SG_ 2365526515 WATT_pBMC_Status_Msg_Check_Seq "Checksum ensures data is valid before use.";
CM_ SG_ 2365526515 WATT_pBalance_State "The state of the BMC in terms of balancing the state of charge of the bottom battery and the top battery.";
CM_ SG_ 2365526515 WATT_pBalance_Error "The error in state of charge existing between the bottom battery and the top battery balanced by the Battery Management Controller (BMC). Positive error corresponds to the lower battery being at a higher state of charge.";
CM_ BO_ 2365526771 "Battery Charger Status Information";
CM_ SG_ 2365526771 WATT_pCharger_Voltage "The voltage output of the battery charger.";
CM_ SG_ 2365526771 WATT_pCharger_Temp_Margin "The smallest difference between an internal battery charger component and its thermal limit.";
CM_ SG_ 2365526771 WATT_pCharger_Temp "The temperature of the battery charger.";
CM_ SG_ 2365526771 WATT_pCharger_State "State of the battery charging process.";
CM_ SG_ 2365526771 WATT_pCharger_Stat_Msg_Check_Seq "Checksum ensures data is valid before use.";
CM_ SG_ 2365526771 WATT_pCharger_Current "The output current of the battery charger.";
CM_ SG_ 2365526771 WATT_pAC_Status "State signifying the presence of an AC Supply on the battery charger.";
CM_ BO_ 2365526003 "Vehicle Energy Information";
CM_ SG_ 2365526003 WATT_pWh_In_Since_Key "The capacity in Watt hours delivered to the battery pack monitored by the Battery Management Controller (BMC), negative for net energy removed from the battery pack.";
CM_ SG_ 2365526003 WATT_pSOC "The State of Charge (SOC) ÿ percent of battery capacity available at current battery health and temperature ÿ of the battery pack monitored by the Battery Management Controller (BMC).";
CM_ SG_ 2365526003 WATT_pEnergy_Msg_Check_Seq "Checksum ensures data is valid before use.";
CM_ SG_ 2365526003 WATT_pAvailable_Wh "The capacity, in Watt hours, of the battery pack monitored by the Battery Management Controller (BMC).";
CM_ BO_ 2298415094 "Perfromance Characteristics of the Motor";
CM_ SG_ 2298415094 WATT_pUpper_Available_Torque "The maximum torque available for accelerating in the positive direction. In overspeed conditions the upper available torque may be negative.";
CM_ SG_ 2298415094 WATT_pPerformance_State "Bits dictating the state of the Electric Propulsion Control Unit or Auxiliary Power Unit from which the message is sent.";
CM_ SG_ 2298415094 WATT_pPerformance_Msg_Check_Seq "Checksum ensures data is valid before use.";
CM_ SG_ 2298415094 WATT_pLower_Available_Torque "The maximum torque available in the reverse direction. Lower available torque is normally negative but can be positive in an negative overspeed condition.";
CM_ SG_ 2298415094 WATT_pActual_Motor_Velocity "Actual RPM of the Electric Propulsion Control Unit or Auxiliary Power Unit from which the message is sent.";
CM_ SG_ 2298415094 WATT_pActual_Motor_torque "The actual motor torque output by the Electric Propulsion Control Unit or Auxiliary Power Unit from which the message is sent.";
CM_ BO_ 2298415350 "Power Information for the Vehicle Motor";
CM_ SG_ 2298415350 WATT_pSpeed_Lim_Cutback_Status "Status bit indicating the ramp down of motor control output and subsequent vehicle performance due to the motor speed exceeding the limits set for the motor.";
CM_ SG_ 2298415350 WATT_pMotor_Therm_Cutback "Status bit indicating the ramp down of motor control output and subsequent vehicle performance due to the temperature of the motor exceeding a predefined value.";
CM_ SG_ 2298415350 WATT_pMotor_Power_Cutback_Status "Status bit indicating the ramp down of motor control output and subsequent vehicle performance due to low power availability.";
CM_ SG_ 2298415350 WATT_pI_DC_Cutback_Status "Status bit indicating the ramp down of motor control output and subsequent vehicle performance due to low Input Current.";
CM_ SG_ 2298415350 WATT_pController_Therm_Cutback "Status bit indicating the ramp down of motor control output and subsequent vehicle performance due to the temperature of the motor controller exceeding a predefined value.";
CM_ SG_ 2298415350 WATT_pPower_Msg_Check_Seq "Checksum ensures data is valid before use.";
CM_ SG_ 2298415350 WATT_pInput_Current "Input DC Current of the Electric Propulsion Control Unit or Auxiliary Power Control Unit from which the message is sent.";
CM_ SG_ 2298415350 WATT_pCapacitor_Voltage "Capacitor Voltage of the Electric Propulsion Control Unit or Auxiliary Power Control Unit from which the message is sent.";
CM_ BO_ 2298415606 "Temperature Information of Electrical System Components";
CM_ SG_ 2298415606 WATT_pTemperature_Msg_Check_Seq "Checksum ensures data is valid before use.";
CM_ SG_ 2298415606 WATT_pMotor_Temp_Margin "The smallest difference between an internal motor component and its thermal limit for the Electric Propulsion Control Unit or Auxiliary Power Control Unit from which the message is sent";
CM_ SG_ 2298415606 WATT_pMotor_Temp "Actual motor temperature of the Electric Propulsion Unit or Auxiliary Power Unit from which the message is sent";
CM_ SG_ 2298415606 WATT_pJunction_Temp "Actual junction temperature of the Electric Propulsion Control Unit or Auxiliary Power Unit from which the message is sent";
CM_ SG_ 2298415606 WATT_pController_Temp_Margin "The smallest difference between an internal component and its thermal limit for the Electric Propulsion Control Unit or Auxiliary Power Control Unit from which the message is sent";
CM_ SG_ 2298415606 WATT_pCapacitor_Temp "Actual capacitor temperature of the Electric Propulsion Control Unit or Auxiliary Power Unit from which the message is sent";
CM_ SG_ 2298415606 WATT_pBoard_Temp "Board temperature of the Electric Propulsion Control Unit or Auxiliary Power Unit from which the message is sent";
CM_ SG_ 2298415606 WATT_pBaseplate_Temp "Actual baseplate temperature of the Electric Propulsion Control Unit or Auxiliary Power Unit from which the message is sent";
CM_ BO_ 2298415095 "Perfromance Characteristics of the Motor";
CM_ SG_ 2298415095 WATT_pUpper_Available_Torque "The maximum torque available for accelerating in the positive direction. In overspeed conditions the upper available torque may be negative.";
CM_ SG_ 2298415095 WATT_pPerformance_State "Bits dictating the state of the Electric Propulsion Control Unit or Auxiliary Power Unit from which the message is sent.";
CM_ SG_ 2298415095 WATT_pPerformance_Msg_Check_Seq "Checksum ensures data is valid before use.";
CM_ SG_ 2298415095 WATT_pLower_Available_Torque "The maximum torque available in the reverse direction. Lower available torque is normally negative but can be positive in an negative overspeed condition.";
CM_ SG_ 2298415095 WATT_pActual_Motor_Velocity "Actual RPM of the Electric Propulsion Control Unit or Auxiliary Power Unit from which the message is sent.";
CM_ SG_ 2298415095 WATT_pActual_Motor_torque "The actual motor torque output by the Electric Propulsion Control Unit or Auxiliary Power Unit from which the message is sent.";
CM_ BO_ 2298415351 "Power Information for the Vehicle Motor";
CM_ SG_ 2298415351 WATT_pSpeed_Lim_Cutback_Status "Status bit indicating the ramp down of motor control output and subsequent vehicle performance due to the motor speed exceeding the limits set for the motor.";
CM_ SG_ 2298415351 WATT_pMotor_Therm_Cutback "Status bit indicating the ramp down of motor control output and subsequent vehicle performance due to the temperature of the motor exceeding a predefined value.";
CM_ SG_ 2298415351 WATT_pMotor_Power_Cutback_Status "Status bit indicating the ramp down of motor control output and subsequent vehicle performance due to low power availability.";
CM_ SG_ 2298415351 WATT_pI_DC_Cutback_Status "Status bit indicating the ramp down of motor control output and subsequent vehicle performance due to low Input Current.";
CM_ SG_ 2298415351 WATT_pController_Therm_Cutback "Status bit indicating the ramp down of motor control output and subsequent vehicle performance due to the temperature of the motor controller exceeding a predefined value.";
CM_ SG_ 2298415351 WATT_pPower_Msg_Check_Seq "Checksum ensures data is valid before use.";
CM_ SG_ 2298415351 WATT_pInput_Current "Input DC Current of the Electric Propulsion Control Unit or Auxiliary Power Control Unit from which the message is sent.";
CM_ SG_ 2298415351 WATT_pCapacitor_Voltage "Capacitor Voltage of the Electric Propulsion Control Unit or Auxiliary Power Control Unit from which the message is sent.";
CM_ BO_ 2298415607 "Temperature Information of Electrical System Components";
CM_ SG_ 2298415607 WATT_pTemperature_Msg_Check_Seq "Checksum ensures data is valid before use.";
CM_ SG_ 2298415607 WATT_pMotor_Temp_Margin "The smallest difference between an internal motor component and its thermal limit for the Electric Propulsion Control Unit or Auxiliary Power Control Unit from which the message is sent";
CM_ SG_ 2298415607 WATT_pMotor_Temp "Actual motor temperature of the Electric Propulsion Unit or Auxiliary Power Unit from which the message is sent";
CM_ SG_ 2298415607 WATT_pJunction_Temp "Actual junction temperature of the Electric Propulsion Control Unit or Auxiliary Power Unit from which the message is sent";
CM_ SG_ 2298415607 WATT_pController_Temp_Margin "The smallest difference between an internal component and its thermal limit for the Electric Propulsion Control Unit or Auxiliary Power Control Unit from which the message is sent";
CM_ SG_ 2298415607 WATT_pCapacitor_Temp "Actual capacitor temperature of the Electric Propulsion Control Unit or Auxiliary Power Unit from which the message is sent";
CM_ SG_ 2298415607 WATT_pBoard_Temp "Board temperature of the Electric Propulsion Control Unit or Auxiliary Power Unit from which the message is sent";
CM_ SG_ 2298415607 WATT_pBaseplate_Temp "Actual baseplate temperature of the Electric Propulsion Control Unit or Auxiliary Power Unit from which the message is sent";
CM_ BO_ 2298415090 "Perfromance Characteristics of the Motor";
CM_ SG_ 2298415090 WATT_pUpper_Available_Torque "The maximum torque available for accelerating in the positive direction. In overspeed conditions the upper available torque may be negative.";
CM_ SG_ 2298415090 WATT_pPerformance_State "Bits dictating the state of the Electric Propulsion Control Unit or Auxiliary Power Unit from which the message is sent.";
CM_ SG_ 2298415090 WATT_pPerformance_Msg_Check_Seq "Checksum ensures data is valid before use.";
CM_ SG_ 2298415090 WATT_pLower_Available_Torque "The maximum torque available in the reverse direction. Lower available torque is normally negative but can be positive in an negative overspeed condition.";
CM_ SG_ 2298415090 WATT_pActual_Motor_Velocity "Actual RPM of the Electric Propulsion Control Unit or Auxiliary Power Unit from which the message is sent.";
CM_ SG_ 2298415090 WATT_pActual_Motor_torque "The actual motor torque output by the Electric Propulsion Control Unit or Auxiliary Power Unit from which the message is sent.";
CM_ BO_ 2298415346 "Power Information for the Vehicle Motor";
CM_ SG_ 2298415346 WATT_pSpeed_Lim_Cutback_Status "Status bit indicating the ramp down of motor control output and subsequent vehicle performance due to the motor speed exceeding the limits set for the motor.";
CM_ SG_ 2298415346 WATT_pMotor_Therm_Cutback "Status bit indicating the ramp down of motor control output and subsequent vehicle performance due to the temperature of the motor exceeding a predefined value.";
CM_ SG_ 2298415346 WATT_pMotor_Power_Cutback_Status "Status bit indicating the ramp down of motor control output and subsequent vehicle performance due to low power availability.";
CM_ SG_ 2298415346 WATT_pI_DC_Cutback_Status "Status bit indicating the ramp down of motor control output and subsequent vehicle performance due to low Input Current.";
CM_ SG_ 2298415346 WATT_pController_Therm_Cutback "Status bit indicating the ramp down of motor control output and subsequent vehicle performance due to the temperature of the motor controller exceeding a predefined value.";
CM_ SG_ 2298415346 WATT_pPower_Msg_Check_Seq "Checksum ensures data is valid before use.";
CM_ SG_ 2298415346 WATT_pInput_Current "Input DC Current of the Electric Propulsion Control Unit or Auxiliary Power Control Unit from which the message is sent.";
CM_ SG_ 2298415346 WATT_pCapacitor_Voltage "Capacitor Voltage of the Electric Propulsion Control Unit or Auxiliary Power Control Unit from which the message is sent.";
CM_ BO_ 2298415602 "Temperature Information of Electrical System Components";
CM_ SG_ 2298415602 WATT_pTemperature_Msg_Check_Seq "Checksum ensures data is valid before use.";
CM_ SG_ 2298415602 WATT_pMotor_Temp_Margin "The smallest difference between an internal motor component and its thermal limit for the Electric Propulsion Control Unit or Auxiliary Power Control Unit from which the message is sent";
CM_ SG_ 2298415602 WATT_pMotor_Temp "Actual motor temperature of the Electric Propulsion Unit or Auxiliary Power Unit from which the message is sent";
CM_ SG_ 2298415602 WATT_pJunction_Temp "Actual junction temperature of the Electric Propulsion Control Unit or Auxiliary Power Unit from which the message is sent";
CM_ SG_ 2298415602 WATT_pController_Temp_Margin "The smallest difference between an internal component and its thermal limit for the Electric Propulsion Control Unit or Auxiliary Power Control Unit from which the message is sent";
CM_ SG_ 2298415602 WATT_pCapacitor_Temp "Actual capacitor temperature of the Electric Propulsion Control Unit or Auxiliary Power Unit from which the message is sent";
CM_ SG_ 2298415602 WATT_pBoard_Temp "Board temperature of the Electric Propulsion Control Unit or Auxiliary Power Unit from which the message is sent";
CM_ SG_ 2298415602 WATT_pBaseplate_Temp "Actual baseplate temperature of the Electric Propulsion Control Unit or Auxiliary Power Unit from which the message is sent";
CM_ BO_ 2298415089 "Perfromance Characteristics of the Motor";
CM_ SG_ 2298415089 WATT_pUpper_Available_Torque "The maximum torque available for accelerating in the positive direction. In overspeed conditions the upper available torque may be negative.";
CM_ SG_ 2298415089 WATT_pPerformance_State "Bits dictating the state of the Electric Propulsion Control Unit or Auxiliary Power Unit from which the message is sent.";
CM_ SG_ 2298415089 WATT_pPerformance_Msg_Check_Seq "Checksum ensures data is valid before use.";
CM_ SG_ 2298415089 WATT_pLower_Available_Torque "The maximum torque available in the reverse direction. Lower available torque is normally negative but can be positive in an negative overspeed condition.";
CM_ SG_ 2298415089 WATT_pActual_Motor_Velocity "Actual RPM of the Electric Propulsion Control Unit or Auxiliary Power Unit from which the message is sent.";
CM_ SG_ 2298415089 WATT_pActual_Motor_torque "The actual motor torque output by the Electric Propulsion Control Unit or Auxiliary Power Unit from which the message is sent.";
CM_ BO_ 2298415345 "Power Information for the Vehicle Motor";
CM_ SG_ 2298415345 WATT_pSpeed_Lim_Cutback_Status "Status bit indicating the ramp down of motor control output and subsequent vehicle performance due to the motor speed exceeding the limits set for the motor.";
CM_ SG_ 2298415345 WATT_pMotor_Therm_Cutback "Status bit indicating the ramp down of motor control output and subsequent vehicle performance due to the temperature of the motor exceeding a predefined value.";
CM_ SG_ 2298415345 WATT_pMotor_Power_Cutback_Status "Status bit indicating the ramp down of motor control output and subsequent vehicle performance due to low power availability.";
CM_ SG_ 2298415345 WATT_pI_DC_Cutback_Status "Status bit indicating the ramp down of motor control output and subsequent vehicle performance due to low Input Current.";
CM_ SG_ 2298415345 WATT_pController_Therm_Cutback "Status bit indicating the ramp down of motor control output and subsequent vehicle performance due to the temperature of the motor controller exceeding a predefined value.";
CM_ SG_ 2298415345 WATT_pPower_Msg_Check_Seq "Checksum ensures data is valid before use.";
CM_ SG_ 2298415345 WATT_pInput_Current "Input DC Current of the Electric Propulsion Control Unit or Auxiliary Power Control Unit from which the message is sent.";
CM_ SG_ 2298415345 WATT_pCapacitor_Voltage "Capacitor Voltage of the Electric Propulsion Control Unit or Auxiliary Power Control Unit from which the message is sent.";
CM_ BO_ 2298415601 "Temperature Information of Electrical System Components";
CM_ SG_ 2298415601 WATT_pTemperature_Msg_Check_Seq "Checksum ensures data is valid before use.";
CM_ SG_ 2298415601 WATT_pMotor_Temp_Margin "The smallest difference between an internal motor component and its thermal limit for the Electric Propulsion Control Unit or Auxiliary Power Control Unit from which the message is sent";
CM_ SG_ 2298415601 WATT_pMotor_Temp "Actual motor temperature of the Electric Propulsion Unit or Auxiliary Power Unit from which the message is sent";
CM_ SG_ 2298415601 WATT_pJunction_Temp "Actual junction temperature of the Electric Propulsion Control Unit or Auxiliary Power Unit from which the message is sent";
CM_ SG_ 2298415601 WATT_pController_Temp_Margin "The smallest difference between an internal component and its thermal limit for the Electric Propulsion Control Unit or Auxiliary Power Control Unit from which the message is sent";
CM_ SG_ 2298415601 WATT_pCapacitor_Temp "Actual capacitor temperature of the Electric Propulsion Control Unit or Auxiliary Power Unit from which the message is sent";
CM_ SG_ 2298415601 WATT_pBoard_Temp "Board temperature of the Electric Propulsion Control Unit or Auxiliary Power Unit from which the message is sent";
CM_ SG_ 2298415601 WATT_pBaseplate_Temp "Actual baseplate temperature of the Electric Propulsion Control Unit or Auxiliary Power Unit from which the message is sent";
CM_ BO_ 2298415087 "Perfromance Characteristics of the Motor";
CM_ SG_ 2298415087 WATT_pUpper_Available_Torque "The maximum torque available for accelerating in the positive direction. In overspeed conditions the upper available torque may be negative.";
CM_ SG_ 2298415087 WATT_pPerformance_State "Bits dictating the state of the Electric Propulsion Control Unit or Auxiliary Power Unit from which the message is sent.";
CM_ SG_ 2298415087 WATT_pPerformance_Msg_Check_Seq "Checksum ensures data is valid before use.";
CM_ SG_ 2298415087 WATT_pLower_Available_Torque "The maximum torque available in the reverse direction. Lower available torque is normally negative but can be positive in an negative overspeed condition.";
CM_ SG_ 2298415087 WATT_pActual_Motor_Velocity "Actual RPM of the Electric Propulsion Control Unit or Auxiliary Power Unit from which the message is sent.";
CM_ SG_ 2298415087 WATT_pActual_Motor_torque "The actual motor torque output by the Electric Propulsion Control Unit or Auxiliary Power Unit from which the message is sent.";
CM_ BO_ 2298415343 "Power Information for the Vehicle Motor";
CM_ SG_ 2298415343 WATT_pController_Therm_Cutback "Status bit indicating the ramp down of motor control output and subsequent vehicle performance due to the temperature of the motor controller exceeding a predefined value.";
CM_ SG_ 2298415343 WATT_pSpeed_Lim_Cutback_Status "Status bit indicating the ramp down of motor control output and subsequent vehicle performance due to the motor speed exceeding the limits set for the motor.";
CM_ SG_ 2298415343 WATT_pMotor_Therm_Cutback "Status bit indicating the ramp down of motor control output and subsequent vehicle performance due to the temperature of the motor exceeding a predefined value.";
CM_ SG_ 2298415343 WATT_pMotor_Power_Cutback_Status "Status bit indicating the ramp down of motor control output and subsequent vehicle performance due to low power availability.";
CM_ SG_ 2298415343 WATT_pI_DC_Cutback_Status "Status bit indicating the ramp down of motor control output and subsequent vehicle performance due to low Input Current.";
CM_ SG_ 2298415343 WATT_pPower_Msg_Check_Seq "Checksum ensures data is valid before use.";
CM_ SG_ 2298415343 pInput_Current "Input DC Current of the Electric Propulsion Control Unit or Auxiliary Power Control Unit from which the message is sent.";
CM_ SG_ 2298415343 pCapacitor_Voltage "Capacitor Voltage of the Electric Propulsion Control Unit or Auxiliary Power Control Unit from which the message is sent.";
CM_ BO_ 2298415599 "Temperature Information of Electrical System Components";
CM_ SG_ 2298415599 WATT_pTemperature_Msg_Check_Seq "Checksum ensures data is valid before use.";
CM_ SG_ 2298415599 WATT_pMotor_Temp_Margin "The smallest difference between an internal motor component and its thermal limit for the Electric Propulsion Control Unit or Auxiliary Power Control Unit from which the message is sent";
CM_ SG_ 2298415599 WATT_pMotor_Temp "Actual motor temperature of the Electric Propulsion Unit or Auxiliary Power Unit from which the message is sent";
CM_ SG_ 2298415599 WATT_pJunction_Temp "Actual junction temperature of the Electric Propulsion Control Unit or Auxiliary Power Unit from which the message is sent";
CM_ SG_ 2298415599 WATT_pController_Temp_Margin "The smallest difference between an internal component and its thermal limit for the Electric Propulsion Control Unit or Auxiliary Power Control Unit from which the message is sent";
CM_ SG_ 2298415599 WATT_pCapacitor_Temp "Actual capacitor temperature of the Electric Propulsion Control Unit or Auxiliary Power Unit from which the message is sent";
CM_ SG_ 2298415599 WATT_pBoard_Temp "Board temperature of the Electric Propulsion Control Unit or Auxiliary Power Unit from which the message is sent";
CM_ SG_ 2298415599 WATT_pBaseplate_Temp "Actual baseplate temperature of the Electric Propulsion Control Unit or Auxiliary Power Unit from which the message is sent";
CM_ BO_ 2365525248 "BMC 4 Control Information";
CM_ SG_ 2365525248 WATT_pBMC_4_ZeroEnergy_Voltage "The minimum battery voltage required for nominal acceleration and top speed performance. This is for the fourth Battery Management Controller (BMC).";
CM_ SG_ 2365525248 WATT_pBMC_4_ZeroEnergy_Current "Battery current required for minimal acceptable acceleration and top speed performance at the zero energy voltage (ZEV).";
CM_ SG_ 2365525248 WATT_pBMC_4_Shutdown "Setting Shutdown to 1 while the AC_ON input is low will override the status of the key switch input, causing the KL15 input to go low and the BMC to enter the Track state.";
CM_ BO_ 2365524992 "BMC 3 Control Information";
CM_ SG_ 2365524992 WATT_pBMC_3_ZeroEnergy_Voltage "The minimum battery voltage required for nominal acceleration and top speed performance. This is for the third Battery Management Controller (BMC).";
CM_ SG_ 2365524992 WATT_pBMC_3_ZeroEnergy_Current "Battery current required for minimal acceptable acceleration and top speed performance at the zero energy voltage (ZEV).
";
CM_ SG_ 2365524992 WATT_pBMC_3_Shutdown "Setting Shutdown to 1 while the AC_ON input is low will override the status of the key switch input, causing the KL15 input to go low and the BMC to enter the Track state.";
CM_ BO_ 2365524736 "BMC 2 Control Information";
CM_ SG_ 2365524736 WATT_pBMC_2_ZeroEnergy_Voltage "The minimum battery voltage required for nominal acceleration and top speed performance. This is for the second Battery Management Controller (BMC).";
CM_ SG_ 2365524736 WATT_pBMC_2_ZeroEnergy_Current "Battery current required for minimal acceptable acceleration and top speed performance at the zero energy voltage (ZEV).";
CM_ SG_ 2365524736 WATT_pBMC_2_Shutdown "Setting Shutdown to 1 while the AC_ON input is low will override the status of the key switch input, causing the KL15 input to go low and the BMC to enter the Track state. This is for the second Battery Management Controller (BMC).";
CM_ BO_ 2365524480 "BMC 1 Control Information";
CM_ SG_ 2365524480 WATT_pBMC_1_ZeroEnergy_Voltage "The minimum battery voltage required for nominal acceleration and top speed performance. This is for the first or only Battery Management Controller (BMC).";
CM_ SG_ 2365524480 WATT_pBMC_1_ZeroEnergy_Current "Battery current required for minimal acceptable acceleration and top speed performance at the zero energy voltage (ZEV).";
CM_ SG_ 2365524480 WATT_pBMC_1_Shutdown "Setting Shutdown to 1 while the AC_ON input is low will override the status of the key switch input, causing the KL15 input to go low and the BMC to enter the Track state. This is for the first or only Battery Management Controller (BMC).";
CM_ BO_ 2231305728 "Fourth on-board device used to provide auxiliary power, such as electrical, hydraulic, pneumatic, or rotary.";
CM_ SG_ 2231305728 WATT_pAPU_4_Var_4 "This is the Auxiliary Power Unit 4 variable 4";
CM_ SG_ 2231305728 WATT_pAPU_4_Var_3 "This is the Auxiliary Power Unit 4 variable 3";
CM_ SG_ 2231305728 WATT_pAPU_4_Var_2 "This is the Auxiliary Power Unit 4 variable 2";
CM_ SG_ 2231305728 WATT_pAPU_4_Var_1 "This is the Auxiliary Power Unit 4 variable 1";
CM_ SG_ 2231305728 WATT_pAPU_4_cntrl "Bits dictating the commanded control mode of the first or only on-board device used to provide auxiliary power, such as electrical, hydraulic, pneumatic, or rotary.";
CM_ SG_ 2231305728 WATT_pAPU_4_Check_Sequence "Checksum ensures data is valid before use.";
CM_ BO_ 2231305472 "Third on-board device used to provide auxiliary power, such as electrical, hydraulic, pneumatic, or rotary.";
CM_ SG_ 2231305472 WATT_pAPU_3_Var_4 "This is the Auxiliary Power Unit 3 variable 4";
CM_ SG_ 2231305472 WATT_pAPU_3_Var_3 "This is the Auxiliary Power Unit 3 variable 3";
CM_ SG_ 2231305472 WATT_pAPU_3_Var_2 "This is the Auxiliary Power Unit 3 variable 2";
CM_ SG_ 2231305472 WATT_pAPU_3_Var_1 "This is the Auxiliary Power Unit 3 variable 1";
CM_ SG_ 2231305472 WATT_pAPU_3_cntrl "Bits dictating the commanded control mode of the first or only on-board device used to provide auxiliary power, such as electrical, hydraulic, pneumatic, or rotary.";
CM_ SG_ 2231305472 WATT_pAPU_3_Check_Sequence "Checksum ensures data is valid before use.";
CM_ BO_ 2231305216 "Second on-board device used to provide auxiliary power, such as electrical, hydraulic, pneumatic, or rotary.";
CM_ SG_ 2231305216 WATT_pAPU_2_Var_4 "This is the Auxiliary Power Unit 2 variable 4";
CM_ SG_ 2231305216 WATT_pAPU_2_Var_3 "This is the Auxiliary Power Unit 2 variable 3";
CM_ SG_ 2231305216 WATT_pAPU_2_Var_2 "This is the Auxiliary Power Unit 2 variable 2";
CM_ SG_ 2231305216 WATT_pAPU_2_Var_1 "This is the Auxiliary Power Unit 2 variable 1";
CM_ SG_ 2231305216 WATT_pAPU_2_cntrl "Bits dictating the commanded control mode of the first or only on-board device used to provide auxiliary power, such as electrical, hydraulic, pneumatic, or rotary.";
CM_ SG_ 2231305216 WATT_pAPU_2_Check_Sequence "Checksum ensures data is valid before use.";
CM_ BO_ 2231304960 "First or only on-board device used to provide auxiliary power, such as electrical, hydraulic, pneumatic, or rotary.";
CM_ SG_ 2231304960 WATT_pAPU_1_Var_4 "This is the Auxiliary Power Unit 1 variable 4";
CM_ SG_ 2231304960 WATT_pAPU_1_Var_3 "This is the Auxiliary Power Unit 1 variable 3";
CM_ SG_ 2231304960 WATT_pAPU_1_Var_2 "This is the Auxiliary Power Unit 1 variable 2";
CM_ SG_ 2231304960 WATT_pAPU_1_Var_1 "This is the Auxiliary Power Unit 1 variable 1";
CM_ SG_ 2231304960 WATT_pAPU_1_cntrl "Bits dictating the commanded control mode of the first or only on-board device used to provide auxiliary power, such as electrical, hydraulic, pneumatic, or rotary.";
CM_ SG_ 2231304960 WATT_pAPU_1_Check_Sequence "Checksum ensures data is valid before use.";
CM_ BO_ 2231304704 "Fourth on-board device converting torque commands to current commands in an electric vehicle system.";
CM_ SG_ 2231304704 WATT_pEPCU_4_Var_4 "This is the Propulsion Control Unit 4 variable 4";
CM_ SG_ 2231304704 WATT_pEPCU_4_Var_3 "This is the Propulsion Control Unit 4 variable 3";
CM_ SG_ 2231304704 WATT_pEPCU_4_Var_2 "This is the Propulsion Control Unit 4 variable 2";
CM_ SG_ 2231304704 WATT_pEPCU_4_Var_1 "This is the Propulsion Control Unit 4 variable 1";
CM_ SG_ 2231304704 WATT_pEPCU_4_cntrl "Bits dictating the commanded control mode of the fourth on-board device converting torque commands to current commands in an electric vehicle system.";
CM_ SG_ 2231304704 WATT_pEPCU_4_Check_Sequence "Checksum ensures data is valid before use.";
CM_ BO_ 2231304448 "Third on-board device converting torque commands to current commands in an electric vehicle system.";
CM_ SG_ 2231304448 WATT_pEPCU_3_Var_4 "This is the Propulsion Control Unit 3 variable 4";
CM_ SG_ 2231304448 WATT_pEPCU_3_Var_3 "This is the Propulsion Control Unit 3 variable 3";
CM_ SG_ 2231304448 WATT_pEPCU_3_Var_2 "This is the Propulsion Control Unit 3 variable 2";
CM_ SG_ 2231304448 WATT_pEPCU_3_Var_1 "This is the Propulsion Control Unit 3 variable 1";
CM_ SG_ 2231304448 WATT_pEPCU_3_Check_Sequence "Checksum ensures data is valid before use.";
CM_ SG_ 2231304448 WATT_pEPCU_3_cntrl "Bits dictating the commanded control mode of the third on-board device converting torque commands to current commands in an electric vehicle system.";
CM_ BO_ 2231304192 "Second on-board device converting torque commands to current commands in an electric vehicle system.";
CM_ SG_ 2231304192 WATT_pEPCU_2_Check_Sequence "Checksum ensures data is valid before use.";
CM_ SG_ 2231304192 pEPCU_2_Speed_Limit "This is the Propulsion Control Unit 2 variable 4";
CM_ SG_ 2231304192 pEPCU_2_Counter_Torque_Limit "This is the Propulsion Control Unit 2 variable 3";
CM_ SG_ 2231304192 pEPCU_2_Torque_Demand "This is the Propulsion Control Unit 2 variable 2";
CM_ SG_ 2231304192 pEPCU_2_Message_Counter "This is the Propulsion Control Unit 2 variable 1";
CM_ SG_ 2231304192 pEPCU_2_Cntrl_Mode "Bits dictating the commanded control mode of the second on-board device converting torque commands to current commands in an electric vehicle system.";
CM_ BO_ 2231309056 "First or only on-board device converting torque commands to current commands in an electric vehicle system";
CM_ SG_ 2231309056 Check_Sequence "Checksum ensures data is valid before use. ";
CM_ SG_ 2231309056 pEPCU_1_Speed_Limit "This is the Propulsion Control Unit 1 variable 4";
CM_ SG_ 2231309056 pEPCU_1_Message_Counter "This is the Propulsion Control Unit 1 variable 3";
CM_ SG_ 2231309056 pEPCU_1_Counter_Torque_Limit "This is the Propulsion Control Unit 1 variable 2";
CM_ SG_ 2231309056 pEPCU_1_Torque_Demand "This is the Propulsion Control Unit 1 variable 1";
CM_ SG_ 2231309056 pEPCU_1_CNTRL_MODE "Bits dictating the commanded control mode of the first or only on-board device converting torque commands to current commands in an electric vehicle system.";
CM_ BO_ 2566846206 "Engine Intake and Exhaust Pressure and Temperature Information";
CM_ SG_ 2566846206 ParticulateTrapInletPressure "Not approved for use at Polaris at this time.";
CM_ SG_ 2566846206 EngTurboBoostPressure "The gauge pressure measurement of the air intake manifold.  If there are multiple air pressure sensors in the intake stream, this is the last one in flow direction before entering the combustion chamber.";
CM_ SG_ 2566846206 EngIntakeManifoldTemperature "Temperature of pre-combustion air found in intake manifold of engine air supply system.";
CM_ SG_ 2566846206 EngAirInletPressure "Absolue air pressure at inlet to intake manifold or air box.";
CM_ SG_ 2566846206 AirFilterDifferentialPressure "Not approved for use at Polaris at this time.";
CM_ SG_ 2566846206 EngExhaustGasTemperature "Temperature of combustion byproducts leaving the engine. See SPNs 2433 and 2434 for engines with more than one exhaust gas temperature measurement.";
CM_ SG_ 2566846206 CoolantFilterDiffPressure "Not approved for use at Polaris at this time.";
CM_ SG_ 2566887215 pSuspensionDampingPercentFL "Suspension Damping Percentage - Front Left";
CM_ SG_ 2566857470 pRawBrakeSwitchStatus "Raw Brake Switch Status";
BA_DEF_ BO_  "VFrameFormat" ENUM  "StandardCAN","ExtendedCAN","reserved","J1939PG";
BA_DEF_ SG_  "GenSigSendType" ENUM  "Cyclic","OnWrite","OnWriteWithRepetition","OnChange","OnChangeWithRepetition","IfActive","IfActiveWithRepetition","NoSigSendType";
BA_DEF_ SG_  "GenSigStartValue" INT 0 10000;
BA_DEF_ SG_  "GenSigEVName" STRING ;
BA_DEF_ SG_  "SPN" INT 0 524287;
BA_DEF_ SG_  "SigType" ENUM  "Default","Range","RangeSigned","ASCII","Discrete","Control","ReferencePGN","DTC","StringDelimiter","StringLength","StringLengthControl","MessageCounter","MessageChecksum";
BA_DEF_ SG_  "GenSigILSupport" ENUM  "No","Yes";
BA_DEF_ BO_  "GenMsgCycleTimeFast" INT 0 3600000;
BA_DEF_ BO_  "GenMsgILSupport" ENUM  "No","Yes";
BA_DEF_ BO_  "GenMsgStartDelayTime" INT 0 100000;
BA_DEF_ BO_  "GenMsgCycleTime" INT 0 3600000;
BA_DEF_ BO_  "GenMsgRequestable" INT 0 1;
BA_DEF_ BO_  "GenMsgSendType" ENUM  "cyclic","spontaneous","cyclicIfActive","spontaneousWithDelay","cyclicAndSpontaneous","cyclicAndSpontaneousWithDelay","spontaneousWithRepetition","cyclicIfActiveAndSpontaneousWD";
BA_DEF_DEF_  "VFrameFormat" "J1939PG";
BA_DEF_DEF_  "GenSigSendType" "NoSigSendType";
BA_DEF_DEF_  "GenSigStartValue" 0;
BA_DEF_DEF_  "GenSigEVName" "Env@Nodename_@Signame";
BA_DEF_DEF_  "SPN" 0;
BA_DEF_DEF_  "SigType" "Default";
BA_DEF_DEF_  "GenSigILSupport" "Yes";
BA_DEF_DEF_  "GenMsgCycleTimeFast" 0;
BA_DEF_DEF_  "GenMsgILSupport" "Yes";
BA_DEF_DEF_  "GenMsgStartDelayTime" 0;
BA_DEF_DEF_  "GenMsgCycleTime" 0;
BA_DEF_DEF_  "GenMsgRequestable" 1;
BA_DEF_DEF_  "GenMsgSendType" "cyclic";
BA_ "GenMsgCycleTime" BO_ 2565865739 100;
BA_ "GenMsgCycleTime" BO_ 2561212031 100;
BA_ "GenMsgCycleTime" BO_ 2432658686 100;
BA_ "GenMsgCycleTime" BO_ 2633984766 100;
BA_ "GenMsgCycleTime" BO_ 2566847742 1000;
BA_ "GenMsgCycleTime" BO_ 2566832638 1000;
BA_ "GenMsgCycleTime" BO_ 2432656640 100;
BA_ "GenMsgCycleTime" BO_ 2365525748 10;
BA_ "GenMsgCycleTime" BO_ 2365526516 100;
BA_ "GenMsgCycleTime" BO_ 2365526772 100;
BA_ "GenMsgCycleTime" BO_ 2365526004 100;
BA_ "GenMsgCycleTime" BO_ 2365525747 10;
BA_ "GenMsgCycleTime" BO_ 2365526515 100;
BA_ "GenMsgCycleTime" BO_ 2365526771 100;
BA_ "GenMsgCycleTime" BO_ 2365526003 100;
BA_ "GenMsgCycleTime" BO_ 2298415094 10;
BA_ "GenMsgCycleTime" BO_ 2298415350 100;
BA_ "GenMsgCycleTime" BO_ 2298415606 100;
BA_ "GenMsgCycleTime" BO_ 2298415095 10;
BA_ "GenMsgCycleTime" BO_ 2298415351 100;
BA_ "GenMsgCycleTime" BO_ 2298415607 100;
BA_ "GenMsgCycleTime" BO_ 2298415090 10;
BA_ "GenMsgCycleTime" BO_ 2298415346 100;
BA_ "GenMsgCycleTime" BO_ 2298415602 100;
BA_ "GenMsgCycleTime" BO_ 2298415089 10;
BA_ "GenMsgCycleTime" BO_ 2298415345 100;
BA_ "GenMsgCycleTime" BO_ 2298415601 100;
BA_ "GenMsgCycleTime" BO_ 2298415087 10;
BA_ "GenMsgCycleTime" BO_ 2298415343 100;
BA_ "GenMsgCycleTime" BO_ 2298415599 100;
BA_ "GenMsgCycleTime" BO_ 2231305728 10;
BA_ "GenMsgCycleTime" BO_ 2231305472 10;
BA_ "GenMsgCycleTime" BO_ 2231305216 10;
BA_ "GenMsgCycleTime" BO_ 2231304960 10;
BA_ "GenMsgCycleTime" BO_ 2231304704 10;
BA_ "GenMsgCycleTime" BO_ 2231304448 10;
BA_ "GenMsgCycleTime" BO_ 2231304192 10;
BA_ "GenMsgCycleTime" BO_ 2231309056 10;
BA_ "GenMsgCycleTime" BO_ 2566846206 500;
BA_ "GenMsgStartDelayTime" BO_ 2566887215 100;
BA_ "GenMsgCycleTime" BO_ 2566857470 10;
BA_ "SPN" SG_ 2565865739 ABSActive 563;
BA_ "SigType" SG_ 2565865739 ABSActive 1.7E-308;
BA_ "SPN" SG_ 2565865739 ASREngineCtrlActive 561;
BA_ "SigType" SG_ 2565865739 ASREngineCtrlActive 1.7E-308;
BA_ "SPN" SG_ 2565865739 ASRBrakeCtrlActive 562;
BA_ "SigType" SG_ 2565865739 ASRBrakeCtrlActive 1.7E-308;
BA_ "SPN" SG_ 2565865739 BrakePedalPosition 521;
BA_ "SigType" SG_ 2565865739 BrakePedalPosition 1.7E-308;
BA_ "SPN" SG_ 2565865739 ABSOffroadSwitch 575;
BA_ "SigType" SG_ 2565865739 ABSOffroadSwitch 1.7E-308;
BA_ "SPN" SG_ 2565865739 ASROffroadSwitch 576;
BA_ "SigType" SG_ 2565865739 ASROffroadSwitch 1.7E-308;
BA_ "SPN" SG_ 2565865739 ASRHillHolderSwitch 577;
BA_ "SigType" SG_ 2565865739 ASRHillHolderSwitch 1.7E-308;
BA_ "SPN" SG_ 2565865739 EBSBrakeSwitch 1121;
BA_ "SigType" SG_ 2565865739 EBSBrakeSwitch 1.7E-308;
BA_ "SigType" SG_ 2565865739 DL17_TractionCtrlOverrideSwitch 1.7E-308;
BA_ "SPN" SG_ 2565865739 AcceleratorInterlockSwitch 972;
BA_ "SigType" SG_ 2565865739 AcceleratorInterlockSwitch 1.7E-308;
BA_ "SPN" SG_ 2565865739 EngineDerateSwitch 971;
BA_ "SigType" SG_ 2565865739 EngineDerateSwitch 1.7E-308;
BA_ "SPN" SG_ 2565865739 AuxEngineShutdownSwitch 970;
BA_ "SigType" SG_ 2565865739 AuxEngineShutdownSwitch 1.7E-308;
BA_ "SPN" SG_ 2565865739 RemoteAcceleratorSwitch 969;
BA_ "SigType" SG_ 2565865739 RemoteAcceleratorSwitch 1.7E-308;
BA_ "SPN" SG_ 2565865739 EngineRetarderSelection 973;
BA_ "SigType" SG_ 2565865739 EngineRetarderSelection 1.7E-308;
BA_ "SPN" SG_ 2565865739 ABSFullyOperational 1243;
BA_ "SigType" SG_ 2565865739 ABSFullyOperational 1.7E-308;
BA_ "SPN" SG_ 2565865739 EBSRedWarningState 1439;
BA_ "SigType" SG_ 2565865739 EBSRedWarningState 1.7E-308;
BA_ "SPN" SG_ 2565865739 ABSEBSAmberWarningState 1438;
BA_ "SigType" SG_ 2565865739 ABSEBSAmberWarningState 1.7E-308;
BA_ "SPN" SG_ 2565865739 SourceAddress 1481;
BA_ "SigType" SG_ 2565865739 SourceAddress 1.7E-308;
BA_ "SPN" SG_ 2565865739 ATC_ASR_InfoSig 1793;
BA_ "SigType" SG_ 2565865739 ATC_ASR_InfoSig 1.7E-308;
BA_ "SPN" SG_ 2561212031 TextDisplayInstructions 3613;
BA_ "SigType" SG_ 2561212031 TextDisplayInstructions 1.7E-308;
BA_ "SPN" SG_ 2561212031 TextDisplayCharacter 3615;
BA_ "SigType" SG_ 2561212031 TextDisplayCharacter 1.7E-308;
BA_ "SPN" SG_ 2561212031 TextDisplayIndex 3614;
BA_ "SigType" SG_ 2561212031 TextDisplayIndex 1.7E-308;
BA_ "SPN" SG_ 2432658686 pOperatorButton42 520468;
BA_ "SPN" SG_ 2432658686 pOperatorButton41 520467;
BA_ "SPN" SG_ 2432658686 pOperatorButton39 524071;
BA_ "SPN" SG_ 2432658686 pOperatorButton37 524069;
BA_ "SPN" SG_ 2432658686 pOperatorButton36 524068;
BA_ "SPN" SG_ 2432658686 pFOCCMessageCounter 524082;
BA_ "SPN" SG_ 2432658686 pFOCCChecksum 524081;
BA_ "SPN" SG_ 2432658686 pOperatorButton40 524072;
BA_ "SPN" SG_ 2432658686 pOperatorButton38 524070;
BA_ "SPN" SG_ 2432658686 pOperatorButton35 524066;
BA_ "SPN" SG_ 2432658686 pOperatorButton34 524065;
BA_ "SPN" SG_ 2432658686 pOperatorButton33 524064;
BA_ "SPN" SG_ 2432658686 pOperatorButton32 524063;
BA_ "SPN" SG_ 2432658686 pOperatorButton31 524062;
BA_ "SPN" SG_ 2432658686 pOperatorButton30 524061;
BA_ "SPN" SG_ 2432658686 pOperatorButton29 524060;
BA_ "SPN" SG_ 2633984766 pHeatedGripEnable 520366;
BA_ "SPN" SG_ 2633984766 pSideStandStatus 524098;
BA_ "SigType" SG_ 2633984766 pSideStandStatus 1.7E-308;
BA_ "SPN" SG_ 2633984766 pTetherSwitchStatus 520600;
BA_ "SPN" SG_ 2633984766 pLowFuelIndicatorStatus 524087;
BA_ "SPN" SG_ 2633984766 pOperatorNotInOperatingStation 2832;
BA_ "SPN" SG_ 2633984766 pParkBrakeIndicatorStatus 524271;
BA_ "SPN" SG_ 2633984766 pADCRequested 524139;
BA_ "SPN" SG_ 2633984766 pAWDModeRequested 524138;
BA_ "SPN" SG_ 2633984766 pRWDModeRequested 524137;
BA_ "SPN" SG_ 2633984766 pTurfModeRequested 524136;
BA_ "SPN" SG_ 2633984766 pADCStatus 524013;
BA_ "SigType" SG_ 2633984766 pADCStatus 1.7E-308;
BA_ "SPN" SG_ 2633984766 pTreadleNeutralStatus 524017;
BA_ "SigType" SG_ 2633984766 pTreadleNeutralStatus 1.7E-308;
BA_ "SPN" SG_ 2633984766 pTreadleReverseStatus 524018;
BA_ "SigType" SG_ 2633984766 pTreadleReverseStatus 1.7E-308;
BA_ "SPN" SG_ 2633984766 pSecurityLightStatus 524019;
BA_ "SigType" SG_ 2633984766 pSecurityLightStatus 1.7E-308;
BA_ "SPN" SG_ 2633984766 pHighBeamIndicatorStatus 524084;
BA_ "SigType" SG_ 2633984766 pHighBeamIndicatorStatus 1.7E-308;
BA_ "SPN" SG_ 2633984766 pHeatedGripsPercentage 524096;
BA_ "SigType" SG_ 2633984766 pHeatedGripsPercentage 1.7E-308;
BA_ "SPN" SG_ 2633984766 pCruiseControlSetStatus 524097;
BA_ "SigType" SG_ 2633984766 pCruiseControlSetStatus 1.7E-308;
BA_ "SPN" SG_ 2633984766 pSeatBeltIndicatorStatus 524092;
BA_ "SigType" SG_ 2633984766 pSeatBeltIndicatorStatus 1.7E-308;
BA_ "SPN" SG_ 2566847742 WasherFluidLevel 80;
BA_ "SigType" SG_ 2566847742 WasherFluidLevel 1.7E-308;
BA_ "SPN" SG_ 2566847742 FuelLevel 96;
BA_ "SigType" SG_ 2566847742 FuelLevel 1.7E-308;
BA_ "SPN" SG_ 2566847742 FuelFilterDiffPressure 95;
BA_ "SigType" SG_ 2566847742 FuelFilterDiffPressure 1.7E-308;
BA_ "SPN" SG_ 2566847742 EngineOilFilterDiffPressure 99;
BA_ "SigType" SG_ 2566847742 EngineOilFilterDiffPressure 1.7E-308;
BA_ "SPN" SG_ 2566847742 CargoAmbientTemperature 169;
BA_ "SigType" SG_ 2566847742 CargoAmbientTemperature 1.7E-308;
BA_ "SPN" SG_ 2566832638 HighResolTotalVehicleDistance 917;
BA_ "SigType" SG_ 2566832638 HighResolTotalVehicleDistance 1.7E-308;
BA_ "SPN" SG_ 2566832638 HighResolTripDistance 918;
BA_ "SigType" SG_ 2566832638 HighResolTripDistance 1.7E-308;
BA_ "SPN" SG_ 2432656640 pOperatorButton29 524060;
BA_ "SPN" SG_ 2432656640 pOperatorButton1 524059;
BA_ "SigType" SG_ 2432656640 pOperatorButton1 1.7E-308;
BA_ "SPN" SG_ 2432656640 pOperatorButton2 524058;
BA_ "SigType" SG_ 2432656640 pOperatorButton2 1.7E-308;
BA_ "SPN" SG_ 2432656640 pOperatorButton3 524057;
BA_ "SigType" SG_ 2432656640 pOperatorButton3 1.7E-308;
BA_ "SPN" SG_ 2432656640 pOperatorButton4 524056;
BA_ "SigType" SG_ 2432656640 pOperatorButton4 1.7E-308;
BA_ "SPN" SG_ 2432656640 pOperatorButton5 524055;
BA_ "SigType" SG_ 2432656640 pOperatorButton5 1.7E-308;
BA_ "SPN" SG_ 2432656640 pOperatorButton6 524054;
BA_ "SigType" SG_ 2432656640 pOperatorButton6 1.7E-308;
BA_ "SPN" SG_ 2432656640 pOperatorButton7 524053;
BA_ "SigType" SG_ 2432656640 pOperatorButton7 1.7E-308;
BA_ "SPN" SG_ 2432656640 pOperatorButton8 524052;
BA_ "SigType" SG_ 2432656640 pOperatorButton8 1.7E-308;
BA_ "SPN" SG_ 2432656640 pOperatorButton9 524051;
BA_ "SigType" SG_ 2432656640 pOperatorButton9 1.7E-308;
BA_ "SPN" SG_ 2432656640 pOperatorButton10 524050;
BA_ "SigType" SG_ 2432656640 pOperatorButton10 1.7E-308;
BA_ "SPN" SG_ 2432656640 pOperatorButton11 524049;
BA_ "SigType" SG_ 2432656640 pOperatorButton11 1.7E-308;
BA_ "SPN" SG_ 2432656640 pOperatorButton12 524048;
BA_ "SigType" SG_ 2432656640 pOperatorButton12 1.7E-308;
BA_ "SPN" SG_ 2432656640 pOperatorButton13 524047;
BA_ "SigType" SG_ 2432656640 pOperatorButton13 1.7E-308;
BA_ "SPN" SG_ 2432656640 pOperatorButton14 524046;
BA_ "SigType" SG_ 2432656640 pOperatorButton14 1.7E-308;
BA_ "SPN" SG_ 2432656640 pOperatorButton15 524045;
BA_ "SigType" SG_ 2432656640 pOperatorButton15 1.7E-308;
BA_ "SPN" SG_ 2432656640 pOperatorButton16 524044;
BA_ "SigType" SG_ 2432656640 pOperatorButton16 1.7E-308;
BA_ "SPN" SG_ 2432656640 pOperatorButton17 524043;
BA_ "SigType" SG_ 2432656640 pOperatorButton17 1.7E-308;
BA_ "SPN" SG_ 2432656640 pOperatorButton18 524042;
BA_ "SigType" SG_ 2432656640 pOperatorButton18 1.7E-308;
BA_ "SPN" SG_ 2432656640 pOperatorButton19 524041;
BA_ "SigType" SG_ 2432656640 pOperatorButton19 1.7E-308;
BA_ "SPN" SG_ 2432656640 pOperatorButton20 524040;
BA_ "SigType" SG_ 2432656640 pOperatorButton20 1.7E-308;
BA_ "SPN" SG_ 2432656640 pOperatorButton21 524039;
BA_ "SigType" SG_ 2432656640 pOperatorButton21 1.7E-308;
BA_ "SPN" SG_ 2432656640 pOperatorButton22 524038;
BA_ "SigType" SG_ 2432656640 pOperatorButton22 1.7E-308;
BA_ "SPN" SG_ 2432656640 pOperatorButton23 524037;
BA_ "SigType" SG_ 2432656640 pOperatorButton23 1.7E-308;
BA_ "SPN" SG_ 2432656640 pOperatorButton24 524036;
BA_ "SigType" SG_ 2432656640 pOperatorButton24 1.7E-308;
BA_ "SPN" SG_ 2432656640 pOperatorButton25 524035;
BA_ "SigType" SG_ 2432656640 pOperatorButton25 1.7E-308;
BA_ "SPN" SG_ 2432656640 pOperatorButton26 524034;
BA_ "SigType" SG_ 2432656640 pOperatorButton26 1.7E-308;
BA_ "SPN" SG_ 2432656640 pOperatorButton27 520322;
BA_ "SigType" SG_ 2432656640 pOperatorButton27 1.7E-308;
BA_ "SPN" SG_ 2432656640 pOperatorButton28 524032;
BA_ "SigType" SG_ 2432656640 pOperatorButton28 1.7E-308;
BA_ "SPN" SG_ 2432656640 pSideStandStatus 524098;
BA_ "SigType" SG_ 2432656640 pSideStandStatus 1.7E-308;
BA_ "SPN" SG_ 2566804212 NetBattCurrentHiRange 2579;
BA_ "SPN" SG_ 2566804211 NetBattCurrentHiRange 2579;
BA_ "SPN" SG_ 2365525748 WATT_pPack_Voltage 524217;
BA_ "SPN" SG_ 2365525748 WATT_pPack_Current 524216;
BA_ "SPN" SG_ 2365525748 WATT_pDischarge_Limit 524218;
BA_ "SPN" SG_ 2365525748 WATT_pCharge_Limit 524219;
BA_ "SPN" SG_ 2365525748 WATT_pBMC_Pwr_Msg_Check_Seq 524252;
BA_ "SPN" SG_ 2365526516 WATT_pBMCStatusCntr 524273;
BA_ "SPN" SG_ 2365526516 WATT_pBatteryType 520404;
BA_ "SPN" SG_ 2365526516 WATT_pWAKE_State 524230;
BA_ "SPN" SG_ 2365526516 WATT_pKEY_State 524232;
BA_ "SPN" SG_ 2365526516 WATT_pDC_DC_State 524233;
BA_ "SPN" SG_ 2365526516 WATT_pBMC_Temp 524227;
BA_ "SPN" SG_ 2365526516 WATT_pBMC_Status_Msg_Check_Seq 524255;
BA_ "SPN" SG_ 2365526516 WATT_pBalance_State 524229;
BA_ "SPN" SG_ 2365526516 WATT_pBalance_Error 524228;
BA_ "SPN" SG_ 2365526772 WATT_pCharger_Voltage 524235;
BA_ "SPN" SG_ 2365526772 WATT_pCharger_Temp_Margin 524237;
BA_ "SPN" SG_ 2365526772 WATT_pCharger_Temp 524236;
BA_ "SPN" SG_ 2365526772 WATT_pCharger_State 524239;
BA_ "SPN" SG_ 2365526772 WATT_pCharger_Stat_Msg_Check_Seq 524256;
BA_ "SPN" SG_ 2365526772 WATT_pCharger_Current 524234;
BA_ "SPN" SG_ 2365526772 WATT_pAC_Status 524238;
BA_ "SPN" SG_ 2365526004 WATT_pWh_In_Since_Key 524222;
BA_ "SPN" SG_ 2365526004 WATT_pSOC 524220;
BA_ "SPN" SG_ 2365526004 WATT_pEnergy_Msg_Check_Seq 524253;
BA_ "SPN" SG_ 2365526004 WATT_pAvailable_Wh 524221;
BA_ "SPN" SG_ 2365525747 WATT_pPack_Voltage 524217;
BA_ "SPN" SG_ 2365525747 WATT_pPack_Current 524216;
BA_ "SPN" SG_ 2365525747 WATT_pDischarge_Limit 524218;
BA_ "SPN" SG_ 2365525747 WATT_pCharge_Limit 524219;
BA_ "SPN" SG_ 2365525747 WATT_pBMC_Pwr_Msg_Check_Seq 524252;
BA_ "SPN" SG_ 2365526515 WATT_pBMCStatusCntr 524273;
BA_ "SPN" SG_ 2365526515 WATT_pBatteryType 520404;
BA_ "SPN" SG_ 2365526515 WATT_pWAKE_State 524230;
BA_ "SPN" SG_ 2365526515 WATT_pKEY_State 524232;
BA_ "SPN" SG_ 2365526515 WATT_pDC_DC_State 524233;
BA_ "SPN" SG_ 2365526515 WATT_pBMC_Temp 524227;
BA_ "SPN" SG_ 2365526515 WATT_pBMC_Status_Msg_Check_Seq 524255;
BA_ "SPN" SG_ 2365526515 WATT_pBalance_State 524229;
BA_ "SPN" SG_ 2365526515 WATT_pBalance_Error 524228;
BA_ "SPN" SG_ 2365526771 WATT_pCharger_Voltage 524235;
BA_ "SPN" SG_ 2365526771 WATT_pCharger_Temp_Margin 524237;
BA_ "SPN" SG_ 2365526771 WATT_pCharger_Temp 524236;
BA_ "SPN" SG_ 2365526771 WATT_pCharger_State 524239;
BA_ "SPN" SG_ 2365526771 WATT_pCharger_Stat_Msg_Check_Seq 524256;
BA_ "SPN" SG_ 2365526771 WATT_pCharger_Current 524234;
BA_ "SPN" SG_ 2365526771 WATT_pAC_Status 524238;
BA_ "SPN" SG_ 2365526003 WATT_pWh_In_Since_Key 524222;
BA_ "SPN" SG_ 2365526003 WATT_pSOC 524220;
BA_ "SPN" SG_ 2365526003 WATT_pEnergy_Msg_Check_Seq 524253;
BA_ "SPN" SG_ 2365526003 WATT_pAvailable_Wh 524221;
BA_ "SPN" SG_ 2298415094 WATT_pUpper_Available_Torque 524192;
BA_ "SPN" SG_ 2298415094 WATT_pPerformance_State 524190;
BA_ "SPN" SG_ 2298415094 WATT_pPerformance_Msg_Check_Seq 524249;
BA_ "SPN" SG_ 2298415094 WATT_pLower_Available_Torque 524193;
BA_ "SPN" SG_ 2298415094 WATT_pActual_Motor_Velocity 524194;
BA_ "SPN" SG_ 2298415094 WATT_pActual_Motor_torque 524191;
BA_ "SPN" SG_ 2298415350 WATT_pSpeed_Lim_Cutback_Status 524258;
BA_ "SPN" SG_ 2298415350 WATT_pMotor_Therm_Cutback 524260;
BA_ "SPN" SG_ 2298415350 WATT_pMotor_Power_Cutback_Status 524240;
BA_ "SPN" SG_ 2298415350 WATT_pI_DC_Cutback_Status 524257;
BA_ "SPN" SG_ 2298415350 WATT_pController_Therm_Cutback 524259;
BA_ "SPN" SG_ 2298415350 WATT_pPower_Msg_Check_Seq 524250;
BA_ "SPN" SG_ 2298415350 WATT_pInput_Current 524195;
BA_ "SPN" SG_ 2298415350 WATT_pCapacitor_Voltage 524196;
BA_ "SPN" SG_ 2298415606 WATT_pTemperature_Msg_Check_Seq 524251;
BA_ "SPN" SG_ 2298415606 WATT_pMotor_Temp_Margin 524198;
BA_ "SPN" SG_ 2298415606 WATT_pMotor_Temp 524201;
BA_ "SPN" SG_ 2298415606 WATT_pJunction_Temp 524203;
BA_ "SPN" SG_ 2298415606 WATT_pController_Temp_Margin 524197;
BA_ "SPN" SG_ 2298415606 WATT_pCapacitor_Temp 524202;
BA_ "SPN" SG_ 2298415606 WATT_pBoard_Temp 524200;
BA_ "SPN" SG_ 2298415606 WATT_pBaseplate_Temp 524199;
BA_ "SPN" SG_ 2298415095 WATT_pUpper_Available_Torque 524192;
BA_ "SPN" SG_ 2298415095 WATT_pPerformance_State 524190;
BA_ "SPN" SG_ 2298415095 WATT_pPerformance_Msg_Check_Seq 524249;
BA_ "SPN" SG_ 2298415095 WATT_pLower_Available_Torque 524193;
BA_ "SPN" SG_ 2298415095 WATT_pActual_Motor_Velocity 524194;
BA_ "SPN" SG_ 2298415095 WATT_pActual_Motor_torque 524191;
BA_ "SPN" SG_ 2298415351 WATT_pSpeed_Lim_Cutback_Status 524258;
BA_ "SPN" SG_ 2298415351 WATT_pMotor_Therm_Cutback 524260;
BA_ "SPN" SG_ 2298415351 WATT_pMotor_Power_Cutback_Status 524240;
BA_ "SPN" SG_ 2298415351 WATT_pI_DC_Cutback_Status 524257;
BA_ "SPN" SG_ 2298415351 WATT_pController_Therm_Cutback 524259;
BA_ "SPN" SG_ 2298415351 WATT_pPower_Msg_Check_Seq 524250;
BA_ "SPN" SG_ 2298415351 WATT_pInput_Current 524195;
BA_ "SPN" SG_ 2298415351 WATT_pCapacitor_Voltage 524196;
BA_ "SPN" SG_ 2298415607 WATT_pTemperature_Msg_Check_Seq 524251;
BA_ "SPN" SG_ 2298415607 WATT_pMotor_Temp_Margin 524198;
BA_ "SPN" SG_ 2298415607 WATT_pMotor_Temp 524201;
BA_ "SPN" SG_ 2298415607 WATT_pJunction_Temp 524203;
BA_ "SPN" SG_ 2298415607 WATT_pController_Temp_Margin 524197;
BA_ "SPN" SG_ 2298415607 WATT_pCapacitor_Temp 524202;
BA_ "SPN" SG_ 2298415607 WATT_pBoard_Temp 524200;
BA_ "SPN" SG_ 2298415607 WATT_pBaseplate_Temp 524199;
BA_ "SPN" SG_ 2298415090 WATT_pUpper_Available_Torque 524192;
BA_ "SPN" SG_ 2298415090 WATT_pPerformance_State 524190;
BA_ "SPN" SG_ 2298415090 WATT_pPerformance_Msg_Check_Seq 524249;
BA_ "SPN" SG_ 2298415090 WATT_pLower_Available_Torque 524193;
BA_ "SPN" SG_ 2298415090 WATT_pActual_Motor_Velocity 524194;
BA_ "SPN" SG_ 2298415090 WATT_pActual_Motor_torque 524191;
BA_ "SPN" SG_ 2298415346 WATT_pSpeed_Lim_Cutback_Status 524258;
BA_ "SPN" SG_ 2298415346 WATT_pMotor_Therm_Cutback 524260;
BA_ "SPN" SG_ 2298415346 WATT_pMotor_Power_Cutback_Status 524240;
BA_ "SPN" SG_ 2298415346 WATT_pI_DC_Cutback_Status 524257;
BA_ "SPN" SG_ 2298415346 WATT_pController_Therm_Cutback 524259;
BA_ "SPN" SG_ 2298415346 WATT_pPower_Msg_Check_Seq 524250;
BA_ "SPN" SG_ 2298415346 WATT_pInput_Current 524195;
BA_ "SPN" SG_ 2298415346 WATT_pCapacitor_Voltage 524196;
BA_ "SPN" SG_ 2298415602 WATT_pTemperature_Msg_Check_Seq 524251;
BA_ "SPN" SG_ 2298415602 WATT_pMotor_Temp_Margin 524198;
BA_ "SPN" SG_ 2298415602 WATT_pMotor_Temp 524201;
BA_ "SPN" SG_ 2298415602 WATT_pJunction_Temp 524203;
BA_ "SPN" SG_ 2298415602 WATT_pController_Temp_Margin 524197;
BA_ "SPN" SG_ 2298415602 WATT_pCapacitor_Temp 524202;
BA_ "SPN" SG_ 2298415602 WATT_pBoard_Temp 524200;
BA_ "SPN" SG_ 2298415602 WATT_pBaseplate_Temp 524199;
BA_ "SPN" SG_ 2298415089 WATT_pUpper_Available_Torque 524192;
BA_ "SPN" SG_ 2298415089 WATT_pPerformance_State 524190;
BA_ "SPN" SG_ 2298415089 WATT_pPerformance_Msg_Check_Seq 524249;
BA_ "SPN" SG_ 2298415089 WATT_pLower_Available_Torque 524193;
BA_ "SPN" SG_ 2298415089 WATT_pActual_Motor_Velocity 524194;
BA_ "SPN" SG_ 2298415089 WATT_pActual_Motor_torque 524191;
BA_ "SPN" SG_ 2298415345 WATT_pSpeed_Lim_Cutback_Status 524258;
BA_ "SPN" SG_ 2298415345 WATT_pMotor_Therm_Cutback 524260;
BA_ "SPN" SG_ 2298415345 WATT_pMotor_Power_Cutback_Status 524240;
BA_ "SPN" SG_ 2298415345 WATT_pI_DC_Cutback_Status 524257;
BA_ "SPN" SG_ 2298415345 WATT_pController_Therm_Cutback 524259;
BA_ "SPN" SG_ 2298415345 WATT_pPower_Msg_Check_Seq 524250;
BA_ "SPN" SG_ 2298415345 WATT_pInput_Current 524195;
BA_ "SPN" SG_ 2298415345 WATT_pCapacitor_Voltage 524196;
BA_ "SPN" SG_ 2298415601 WATT_pTemperature_Msg_Check_Seq 524251;
BA_ "SPN" SG_ 2298415601 WATT_pMotor_Temp_Margin 524198;
BA_ "SPN" SG_ 2298415601 WATT_pMotor_Temp 524201;
BA_ "SPN" SG_ 2298415601 WATT_pJunction_Temp 524203;
BA_ "SPN" SG_ 2298415601 WATT_pController_Temp_Margin 524197;
BA_ "SPN" SG_ 2298415601 WATT_pCapacitor_Temp 524202;
BA_ "SPN" SG_ 2298415601 WATT_pBoard_Temp 524200;
BA_ "SPN" SG_ 2298415601 WATT_pBaseplate_Temp 524199;
BA_ "SPN" SG_ 2298415087 WATT_pUpper_Available_Torque 524192;
BA_ "SPN" SG_ 2298415087 WATT_pPerformance_State 524190;
BA_ "SPN" SG_ 2298415087 WATT_pPerformance_Msg_Check_Seq 524249;
BA_ "SPN" SG_ 2298415087 WATT_pLower_Available_Torque 524193;
BA_ "SPN" SG_ 2298415087 WATT_pActual_Motor_Velocity 524194;
BA_ "SPN" SG_ 2298415087 WATT_pActual_Motor_torque 524191;
BA_ "SPN" SG_ 2298415343 WATT_pController_Therm_Cutback 524259;
BA_ "SPN" SG_ 2298415343 WATT_pSpeed_Lim_Cutback_Status 524258;
BA_ "SPN" SG_ 2298415343 WATT_pMotor_Therm_Cutback 524260;
BA_ "SPN" SG_ 2298415343 WATT_pMotor_Power_Cutback_Status 524240;
BA_ "SPN" SG_ 2298415343 WATT_pI_DC_Cutback_Status 524257;
BA_ "SPN" SG_ 2298415343 WATT_pPower_Msg_Check_Seq 524250;
BA_ "SPN" SG_ 2298415343 pInput_Current 524195;
BA_ "GenSigStartValue" SG_ 2298415343 pInput_Current 2048;
BA_ "SPN" SG_ 2298415343 pCapacitor_Voltage 524196;
BA_ "SPN" SG_ 2298415599 WATT_pTemperature_Msg_Check_Seq 524251;
BA_ "SPN" SG_ 2298415599 WATT_pMotor_Temp_Margin 524198;
BA_ "SPN" SG_ 2298415599 WATT_pMotor_Temp 524201;
BA_ "SPN" SG_ 2298415599 WATT_pJunction_Temp 524203;
BA_ "SPN" SG_ 2298415599 WATT_pController_Temp_Margin 524197;
BA_ "SPN" SG_ 2298415599 WATT_pCapacitor_Temp 524202;
BA_ "SPN" SG_ 2298415599 WATT_pBoard_Temp 524200;
BA_ "SPN" SG_ 2298415599 WATT_pBaseplate_Temp 524199;
BA_ "SPN" SG_ 2365525248 WATT_pBMC4_Cmd 524279;
BA_ "SPN" SG_ 2365525248 WATT_pBMC_4_ZeroEnergy_Voltage 524214;
BA_ "SPN" SG_ 2365525248 WATT_pBMC_4_ZeroEnergy_Current 524213;
BA_ "SPN" SG_ 2365525248 WATT_pBMC_4_Shutdown 524215;
BA_ "SPN" SG_ 2365524992 WATT_pBMC3_Cmd 524278;
BA_ "SPN" SG_ 2365524992 WATT_pBMC_3_ZeroEnergy_Voltage 524211;
BA_ "SPN" SG_ 2365524992 WATT_pBMC_3_ZeroEnergy_Current 524210;
BA_ "SPN" SG_ 2365524992 WATT_pBMC_3_Shutdown 524212;
BA_ "SPN" SG_ 2365524736 WATT_pBMC2_Cmd 524277;
BA_ "SPN" SG_ 2365524736 WATT_pBMC_2_ZeroEnergy_Voltage 524208;
BA_ "SPN" SG_ 2365524736 WATT_pBMC_2_ZeroEnergy_Current 524207;
BA_ "SPN" SG_ 2365524736 WATT_pBMC_2_Shutdown 524209;
BA_ "SPN" SG_ 2365524480 WATT_pBMC1_Cmd 524276;
BA_ "SPN" SG_ 2365524480 WATT_pBMC_1_ZeroEnergy_Voltage 524205;
BA_ "SPN" SG_ 2365524480 WATT_pBMC_1_ZeroEnergy_Current 524204;
BA_ "SPN" SG_ 2365524480 WATT_pBMC_1_Shutdown 524206;
BA_ "SPN" SG_ 2231305728 WATT_pAPU_4_Var_4 524188;
BA_ "SPN" SG_ 2231305728 WATT_pAPU_4_Var_3 524187;
BA_ "SPN" SG_ 2231305728 WATT_pAPU_4_Var_2 524186;
BA_ "SPN" SG_ 2231305728 WATT_pAPU_4_Var_1 524185;
BA_ "SPN" SG_ 2231305728 WATT_pAPU_4_cntrl 524189;
BA_ "SPN" SG_ 2231305728 WATT_pAPU_4_Check_Sequence 524248;
BA_ "SPN" SG_ 2231305472 WATT_pAPU_3_Var_4 524183;
BA_ "SPN" SG_ 2231305472 WATT_pAPU_3_Var_3 524182;
BA_ "SPN" SG_ 2231305472 WATT_pAPU_3_Var_2 524181;
BA_ "SPN" SG_ 2231305472 WATT_pAPU_3_Var_1 524180;
BA_ "SPN" SG_ 2231305472 WATT_pAPU_3_cntrl 524184;
BA_ "SPN" SG_ 2231305472 WATT_pAPU_3_Check_Sequence 524247;
BA_ "SPN" SG_ 2231305216 WATT_pAPU_2_Var_4 524178;
BA_ "SPN" SG_ 2231305216 WATT_pAPU_2_Var_3 524177;
BA_ "SPN" SG_ 2231305216 WATT_pAPU_2_Var_2 524176;
BA_ "SPN" SG_ 2231305216 WATT_pAPU_2_Var_1 524175;
BA_ "SPN" SG_ 2231305216 WATT_pAPU_2_cntrl 524179;
BA_ "SPN" SG_ 2231305216 WATT_pAPU_2_Check_Sequence 524246;
BA_ "SPN" SG_ 2231304960 WATT_pAPU_1_Var_4 524173;
BA_ "SPN" SG_ 2231304960 WATT_pAPU_1_Var_3 524172;
BA_ "SPN" SG_ 2231304960 WATT_pAPU_1_Var_2 524171;
BA_ "SPN" SG_ 2231304960 WATT_pAPU_1_Var_1 524170;
BA_ "SPN" SG_ 2231304960 WATT_pAPU_1_cntrl 524174;
BA_ "SPN" SG_ 2231304960 WATT_pAPU_1_Check_Sequence 524246;
BA_ "SPN" SG_ 2231304704 WATT_pEPCU_4_Var_4 524168;
BA_ "SPN" SG_ 2231304704 WATT_pEPCU_4_Var_3 524167;
BA_ "SPN" SG_ 2231304704 WATT_pEPCU_4_Var_2 524166;
BA_ "SPN" SG_ 2231304704 WATT_pEPCU_4_Var_1 524165;
BA_ "SPN" SG_ 2231304704 WATT_pEPCU_4_cntrl 524169;
BA_ "SPN" SG_ 2231304704 WATT_pEPCU_4_Check_Sequence 524244;
BA_ "SPN" SG_ 2231304448 WATT_pEPCU_3_Var_4 524163;
BA_ "SPN" SG_ 2231304448 WATT_pEPCU_3_Var_3 524162;
BA_ "SPN" SG_ 2231304448 WATT_pEPCU_3_Var_2 524161;
BA_ "SPN" SG_ 2231304448 WATT_pEPCU_3_Var_1 524160;
BA_ "SPN" SG_ 2231304448 WATT_pEPCU_3_Check_Sequence 524243;
BA_ "SPN" SG_ 2231304448 WATT_pEPCU_3_cntrl 524164;
BA_ "SPN" SG_ 2231304192 WATT_pEPCU_2_Check_Sequence 524242;
BA_ "SPN" SG_ 2231304192 pEPCU_2_Speed_Limit 524158;
BA_ "SPN" SG_ 2231304192 pEPCU_2_Counter_Torque_Limit 524157;
BA_ "SPN" SG_ 2231304192 pEPCU_2_Torque_Demand 524156;
BA_ "SPN" SG_ 2231304192 pEPCU_2_Message_Counter 524155;
BA_ "SPN" SG_ 2231304192 pEPCU_2_Cntrl_Mode 524159;
BA_ "SPN" SG_ 2231309056 Check_Sequence 524241;
BA_ "SPN" SG_ 2231309056 pEPCU_1_Speed_Limit 524153;
BA_ "SPN" SG_ 2231309056 pEPCU_1_Message_Counter 524152;
BA_ "SPN" SG_ 2231309056 pEPCU_1_Counter_Torque_Limit 524151;
BA_ "SPN" SG_ 2231309056 pEPCU_1_Torque_Demand 524150;
BA_ "SPN" SG_ 2231309056 pEPCU_1_CNTRL_MODE 524154;
BA_ "SPN" SG_ 2566846206 ParticulateTrapInletPressure 81;
BA_ "SigType" SG_ 2566846206 ParticulateTrapInletPressure 1.7E-308;
BA_ "SPN" SG_ 2566846206 EngTurboBoostPressure 102;
BA_ "SigType" SG_ 2566846206 EngTurboBoostPressure 1.7E-308;
BA_ "SPN" SG_ 2566846206 EngIntakeManifoldTemperature 105;
BA_ "SigType" SG_ 2566846206 EngIntakeManifoldTemperature 1.7E-308;
BA_ "SPN" SG_ 2566846206 EngAirInletPressure 106;
BA_ "SigType" SG_ 2566846206 EngAirInletPressure 1.7E-308;
BA_ "SPN" SG_ 2566846206 AirFilterDifferentialPressure 107;
BA_ "SigType" SG_ 2566846206 AirFilterDifferentialPressure 1.7E-308;
BA_ "SPN" SG_ 2566846206 EngExhaustGasTemperature 173;
BA_ "SigType" SG_ 2566846206 EngExhaustGasTemperature 1.7E-308;
BA_ "SPN" SG_ 2566846206 CoolantFilterDiffPressure 112;
BA_ "SigType" SG_ 2566846206 CoolantFilterDiffPressure 1.7E-308;
BA_ "SPN" SG_ 2566887215 pSuspensionMode 524186;
BA_ "SPN" SG_ 2566887215 pSuspensionEventStatuses 524187;
BA_ "SPN" SG_ 2566887215 pSuspensionDampingPercentRR 524287;
BA_ "SPN" SG_ 2566887215 pSuspensionDampingPercentRL 524286;
BA_ "SPN" SG_ 2566887215 pSuspensionDampingPercentFR 524285;
BA_ "SPN" SG_ 2566887215 pSuspensionDampingPercentFL 524284;
BA_ "SPN" SG_ 2566857470 pNormalizedAcceleratorPosition 520574;
BA_ "SPN" SG_ 2566857470 pRawBrakeSwitchStatus 520572;
VAL_ 2565865739 ABSActive 0 "Passive" 1 "Active" 2 "Reserved" 3 "NoAction" ;
VAL_ 2565865739 ASREngineCtrlActive 0 "Passive" 1 "Active" 2 "Reserved" 3 "NoAction" ;
VAL_ 2565865739 ASRBrakeCtrlActive 0 "Passive" 1 "Active" 2 "Reserved" 3 "NoAction" ;
VAL_ 2565865739 ABSOffroadSwitch 0 "Passive" 1 "Active" 2 "Error" 3 "NotAvailable" ;
VAL_ 2565865739 ASROffroadSwitch 0 "Passive" 1 "Active" 2 "Error" 3 "NotAvailable" ;
VAL_ 2565865739 ASRHillHolderSwitch 0 "Passive" 1 "Active" 2 "Error" 3 "NotAvailable" ;
VAL_ 2565865739 EBSBrakeSwitch 0 "Brake pedal is not being pressed" 1 "Brake pedal is being pressed" 2 "Reserved" 3 "Don't care" ;
VAL_ 2565865739 DL17_TractionCtrlOverrideSwitch 0 "Active" 1 "Inactive" 2 "Reserved" 3 "Don't care" ;
VAL_ 2565865739 AcceleratorInterlockSwitch 0 "off" 1 "on" 2 "Reserved" 3 "Don't care" ;
VAL_ 2565865739 EngineDerateSwitch 0 "off" 1 "on" 2 "Reserved" 3 "Don't care" ;
VAL_ 2565865739 AuxEngineShutdownSwitch 0 "off" 1 "on" 2 "Reserved" 3 "Don't care" ;
VAL_ 2565865739 RemoteAcceleratorSwitch 0 "off" 1 "on" 2 "Reserved" 3 "Don't care" ;
VAL_ 2565865739 ABSFullyOperational 0 "not fully operational" 1 "fully operational" 2 "Reserved" 3 "Don't care" ;
VAL_ 2565865739 EBSRedWarningState 0 "off" 1 "on" 2 "Reserved" 3 "Don't care" ;
VAL_ 2565865739 ABSEBSAmberWarningState 0 "off" 1 "on" 2 "Reserved" 3 "Don't care" ;
VAL_ 2565865739 ATC_ASR_InfoSig 0 "Off" 1 "On" 2 "Reserved" 3 "Take no action" ;
VAL_ 2561212031 TextDisplayInstructions 0 "Clear Display" 1 "Hold Display" 2 "Append at end of display" 3 "Overwrite display" 4 "Overwrite substring" 5 "Highlight substring" 6 "Blink substring" 7 "Reserved" 15 "Not applicable" ;
VAL_ 2432658686 pOperatorButton42 3 "Not Available" 2 "Error" 1 "Button pressed" 0 "Button not pressed" ;
VAL_ 2432658686 pOperatorButton41 3 "Not Available" 2 "Error" 1 "Button pressed" 0 "Button not pressed" ;
VAL_ 2432658686 pOperatorButton39 3 "Not Available" 2 "Error" 1 "Button Pressed" 0 "Button Not Pressed" ;
VAL_ 2432658686 pOperatorButton37 3 "Not Available" 2 "Error" 1 "Button Pressed" 0 "Button Not Pressed" ;
VAL_ 2432658686 pOperatorButton36 3 "Not Available" 2 "Error" 1 "Button Pressed" 0 "Button Not Pressed" ;
VAL_ 2432658686 pOperatorButton40 3 "Not Available" 2 "Error" 1 "Enabled" 0 "Disabled" ;
VAL_ 2432658686 pOperatorButton38 3 "Not Available" 2 "Error" 1 "Button Pressed" 0 "Button Not Pressed" ;
VAL_ 2432658686 pOperatorButton35 3 "Not Available" 2 "Error" 1 "Button Pressed" 0 "Button Not Pressed" ;
VAL_ 2432658686 pOperatorButton34 3 "Not Available" 2 "Error" 1 "Button Pressed" 0 "Button Not Pressed" ;
VAL_ 2432658686 pOperatorButton33 3 "Not Available" 2 "Error" 1 "Button Pressed" 0 "Button Not Pressed" ;
VAL_ 2432658686 pOperatorButton32 3 "Not Available" 2 "Error" 1 "Button Pressed" 0 "Button Not Pressed" ;
VAL_ 2432658686 pOperatorButton31 3 "Not Available" 2 "Error" 1 "Button Pressed" 0 "Button Not Pressed" ;
VAL_ 2432658686 pOperatorButton30 3 "Not Available" 2 "Error" 1 "Button Pressed" 0 "Button Not Pressed" ;
VAL_ 2432658686 pOperatorButton29 3 "Not Available" 2 "Error" 1 "Button Pressed" 0 "Button Not Pressed" ;
VAL_ 2633984766 pHeatedGripEnable 3 "Description for the value '3'" 2 "Error Indicator" 1 "Enabled (Installed)" 0 "Disabled (Not installed)" ;
VAL_ 2633984766 pSideStandStatus 3 "Not Available" 2 "Error Indicator" 1 "Side Stand Up" 0 "Side Stand Down" ;
VAL_ 2633984766 pTetherSwitchStatus 3 "Not Available" 2 "Error" 1 "Tether SW Open (disconnected)" 0 "Tether SW Closed (connected)" ;
VAL_ 2633984766 pLowFuelIndicatorStatus 3 "Not Available" 2 "Error" 1 "Low Fuel Indicator On" 0 "Low Fuel Indicator Off" ;
VAL_ 2633984766 pOperatorNotInOperatingStation 3 "Description for the value '3'" 2 "Error" 1 "Operator Not In OperatorStation" 0 "Operator In OperatorStation" ;
VAL_ 2633984766 pParkBrakeIndicatorStatus 7 "Not Available" 6 "Error Indicator" 5 "Available for future use" 4 "Available for future use" 3 "Park Brake Indicator 2 Hz flash" 2 "Park Brake Indicator 1 Hz flash" 1 "Park Brake Indicator On (Solid)" 0 "Park Brake Indicator Off" ;
VAL_ 2633984766 pADCRequested 3 "Not Available" 2 "Error" 1 "ADC Mode Requested" 0 "ADC Mode not Requested" ;
VAL_ 2633984766 pAWDModeRequested 3 "Not Available" 2 "Error" 1 "AWD Mode Requested" 0 "AWD Mode not Requested" ;
VAL_ 2633984766 pRWDModeRequested 3 "Not Available" 2 "Error" 1 "RWD Mode Requested" 0 "RWD Mode not Requested" ;
VAL_ 2633984766 pTurfModeRequested 3 "Not Available" 2 "Error" 1 "Turf Mode Requested" 0 "Turf Mode not Requested" ;
VAL_ 2633984766 pADCStatus 0 "ADC Actuator Not Engaged" 1 "ADC Actuator Engaged" 2 "Error" 3 "Not available" ;
VAL_ 2633984766 pTreadleNeutralStatus 0 "Treadle Neutral Not Engaged" 1 "Treadle Neutral Engaged" 2 "Error" 3 "Not Available" ;
VAL_ 2633984766 pTreadleReverseStatus 0 "Treadle Reverse Not Engaged" 1 "Treadle Reverse Engaged" 2 "Error" 3 "Not Available" ;
VAL_ 2633984766 pSecurityLightStatus 0 "Off" 1 "On (Solid)" 2 "Error (Flashing)" 3 "Not Available" ;
VAL_ 2633984766 pHighBeamIndicatorStatus 0 "Indicator Off" 1 "Indicator On" 2 "Error (Indicator Flashing)" 3 "Not Available" ;
VAL_ 2633984766 pCruiseControlSetStatus 0 "Cruise Not Set" 1 "Cruise Set" 2 "Error (Lamp Flashing)" 3 "Not Available" ;
VAL_ 2633984766 pSeatBeltIndicatorStatus 0 "Seat_Belt_Indicator_Off" 1 "Seat_Belt_Indicator_On_Solid" 2 "Seat_Belt_Indicator_1Hz" 3 "Seat_Belt_Indicator_2Hz" 4 "Future1" 5 "Future2" 6 "Error" 7 "Not_Available" ;
VAL_ 2432656640 pOperatorButton29 3 "Not Available" 2 "Error" 1 "Button Pressed" 0 "Button Not Pressed" ;
VAL_ 2432656640 pOperatorButton1 0 "Not Pressed" 1 "Pressed" 2 "Error" 3 "Not Available" ;
VAL_ 2432656640 pOperatorButton2 0 "Active" 1 "Inactive" 2 "Error" 3 "Not Available" ;
VAL_ 2432656640 pOperatorButton3 0 "Not Pressed" 1 "Pressed" 2 "Error" 3 "Not Available" ;
VAL_ 2432656640 pOperatorButton4 0 "Not Pressed" 1 "Pressed" 2 "Error" 3 "Not Available" ;
VAL_ 2432656640 pOperatorButton5 0 "Not Pressed" 1 "Pressed" 2 "Error" 3 "Not Available" ;
VAL_ 2432656640 pOperatorButton6 0 "Not Pressed" 1 "Pressed" 2 "Error" 3 "Not Available" ;
VAL_ 2432656640 pOperatorButton7 0 "Not Pressed" 1 "Pressed" 2 "Error" 3 "Not Available" ;
VAL_ 2432656640 pOperatorButton8 0 "Not Pressed" 1 "Pressed" 2 "Error" 3 "Not Available" ;
VAL_ 2432656640 pOperatorButton9 0 "Not Pressed" 1 "Pressed" 2 "Error" 3 "Not Available" ;
VAL_ 2432656640 pOperatorButton10 0 "Not Pressed" 1 "Pressed" 2 "Error" 3 "Not Available" ;
VAL_ 2432656640 pOperatorButton11 0 "Not Pressed" 1 "Pressed" 2 "Error" 3 "Not Available" ;
VAL_ 2432656640 pOperatorButton12 0 "Not Pressed" 1 "Pressed" 2 "Error" 3 "Not Available" ;
VAL_ 2432656640 pOperatorButton13 0 "Not Pressed" 1 "Pressed" 2 "Error" 3 "Not Available" ;
VAL_ 2432656640 pOperatorButton14 0 "Not Pressed" 1 "Pressed" 2 "Error" 3 "Not Available" ;
VAL_ 2432656640 pOperatorButton15 0 "Not Pressed" 1 "Pressed" 2 "Error" 3 "Not Available" ;
VAL_ 2432656640 pOperatorButton16 0 "Not Pressed" 1 "Pressed" 2 "Error" 3 "Not Available" ;
VAL_ 2432656640 pOperatorButton17 0 "Not Pressed" 1 "Pressed" 2 "Error" 3 "Not Available" ;
VAL_ 2432656640 pOperatorButton18 0 "Not Pressed" 1 "Pressed" 2 "Error" 3 "Not Available" ;
VAL_ 2432656640 pOperatorButton19 0 "Not Pressed" 1 "Pressed" 2 "Error" 3 "Not Available" ;
VAL_ 2432656640 pOperatorButton20 0 "Not Pressed" 1 "Pressed" 2 "Error" 3 "Not Available" ;
VAL_ 2432656640 pOperatorButton21 0 "Not Pressed" 1 "Pressed" 2 "Error" 3 "Not Available" ;
VAL_ 2432656640 pOperatorButton22 0 "Not Pressed" 1 "Pressed" 2 "Error" 3 "Not Available" ;
VAL_ 2432656640 pOperatorButton23 0 "Not Pressed" 1 "Pressed" 2 "Error" 3 "Not Available" ;
VAL_ 2432656640 pOperatorButton24 0 "Not Pressed" 1 "Pressed" 2 "Error" 3 "Not Available" ;
VAL_ 2432656640 pOperatorButton25 0 "Not Pressed" 1 "Pressed" 2 "Error" 3 "Not Available" ;
VAL_ 2432656640 pOperatorButton26 0 "Not Pressed" 1 "Pressed" 2 "Error" 3 "Not Available" ;
VAL_ 2432656640 pOperatorButton27 0 "Not Pressed" 1 "Pressed" 2 "Error" 3 "Not Available" ;
VAL_ 2432656640 pOperatorButton28 0 "Not Pressed" 1 "Pressed" 2 "Error" 3 "Not Available" ;
VAL_ 2432656640 pSideStandStatus 3 "Not Available" 2 "Error Indicator" 1 "Side Stand Up" 0 "Side Stand Down" ;
VAL_ 2365526516 WATT_pBatteryType 128 "Li-Ion Pack" 70 "AGM Lead Acid 6V" 68 "AGM Lead Acid 12V" 6 "Flooded Lead Acid 6V" 4 "Flooded Lead Acid 12V" ;
VAL_ 2365526516 WATT_pWAKE_State 3 "Not Available" 2 "Error" 1 "Active" 0 "Off" ;
VAL_ 2365526516 WATT_pKEY_State 3 "Not Available" 2 "Error" 1 "On" 0 "Off" ;
VAL_ 2365526516 WATT_pDC_DC_State 7 "Not Available" 6 "Error" 5 "Power, Enabled" 4 "Powered, Disabled" 3 "Reserved" 2 "Reserved" 1 "Reserved" 0 "Off" ;
VAL_ 2365526516 WATT_pBalance_State 15 "Not Available" 14 "Reserved" 13 "Reserved" 12 "Reserved" 11 "Reserved" 10 "Reserved" 9 "Reserved" 8 "Relaxing" 7 "Reserved" 6 "Reserved" 5 "Reserved" 4 "Charging" 3 "Reserved" 2 "Resting" 1 "Driving" 0 "Power Up" ;
VAL_ 2365526772 WATT_pCharger_State 31 "Not Available" 30 "Reserved" 29 "Reserved" 28 "Reserved" 27 "Maintanence Charging" 26 "Equalize,Balance Charging" 25 "Float Charging" 24 "Charge Complete" 23 "Reserved" 22 "Reserved" 21 "Reserved" 20 "Reduced Performance" 19 "Finish Phase" 18 "Absorption Phase" 17 "Bulk Phase" 16 "Recovery Phase" 15 "Reserved" 14 "Reserved" 13 "Reserved" 12 "Reserved" 11 "Reserved" 10 "Reserved" 9 "Reserved" 8 "Reserved" 7 "Reserved" 6 "Internal Fault Shutdown" 5 "Over Temp Shutdown" 4 "Charge Timeout" 3 "Check Battery Shutdown" 2 "Low Voltage Shutdown" 1 "High Voltage Shutdown" 0 "Off" ;
VAL_ 2365526772 WATT_pAC_Status 7 "Not Available" 6 "Error" 5 "220 AC" 4 "220 AC, reduced pwr low Voltage" 3 "110 AC" 2 "110 AC, reduced pwr low Voltage" 1 "AC Present, Voltage Level N/A" 0 "No AC Present" ;
VAL_ 2365526515 WATT_pBatteryType 128 "Li-Ion Pack" 70 "AGM Lead Acid 6V" 68 "AGM Lead Acid 12V" 6 "Flooded Lead Acid 6V" 4 "Flooded Lead Acid 12V" ;
VAL_ 2365526515 WATT_pWAKE_State 3 "Not Available" 2 "Error" 1 "Active" 0 "Off" ;
VAL_ 2365526515 WATT_pKEY_State 3 "Not Available" 2 "Error" 1 "On" 0 "Off" ;
VAL_ 2365526515 WATT_pDC_DC_State 7 "Not Available" 6 "Error" 5 "Power, Enabled" 4 "Powered, Disabled" 3 "Reserved" 2 "Reserved" 1 "Reserved" 0 "Off" ;
VAL_ 2365526515 WATT_pBalance_State 15 "Not Available" 14 "Reserved" 13 "Reserved" 12 "Reserved" 11 "Reserved" 10 "Reserved" 9 "Reserved" 8 "Relaxing" 7 "Reserved" 6 "Reserved" 5 "Reserved" 4 "Charging" 3 "Reserved" 2 "Resting" 1 "Driving" 0 "Power Up" ;
VAL_ 2365526771 WATT_pCharger_State 31 "Not Available" 30 "Reserved" 29 "Reserved" 28 "Reserved" 27 "Maintanence Charging" 26 "Equalize,Balance Charging" 25 "Float Charging" 24 "Charge Complete" 23 "Reserved" 22 "Reserved" 21 "Reserved" 20 "Reduced Performance" 19 "Finish Phase" 18 "Absorption Phase" 17 "Bulk Phase" 16 "Recovery Phase" 15 "Reserved" 14 "Reserved" 13 "Reserved" 12 "Reserved" 11 "Reserved" 10 "Reserved" 9 "Reserved" 8 "Reserved" 7 "Reserved" 6 "Internal Fault Shutdown" 5 "Over Temp Shutdown" 4 "Charge Timeout" 3 "Check Battery Shutdown" 2 "Low Voltage Shutdown" 1 "High Voltage Shutdown" 0 "Off" ;
VAL_ 2365526771 WATT_pAC_Status 7 "Not Available" 6 "Error" 5 "220 AC" 4 "220 AC, reduced pwr low Voltage" 3 "110 AC" 2 "110 AC, reduced pwr low Voltage" 1 "AC Present, Voltage Level N/A" 0 "No AC Present" ;
VAL_ 2298415094 WATT_pPerformance_State 15 "Not Available" 14 "Reserved" 13 "Reserved" 12 "Reserved" 11 "Reserved" 10 "Reserved" 9 "Reserved" 8 "Reserved" 7 "Reserved" 6 "Fault Reaction" 5 "Fault Off" 4 "Enabled" 3 "Energized" 2 "Precharge" 1 "Shutdown" 0 "Initialize" ;
VAL_ 2298415350 WATT_pSpeed_Lim_Cutback_Status 1 "Active" 0 "Inactive" ;
VAL_ 2298415350 WATT_pMotor_Therm_Cutback 1 "Active" 0 "Inactive" ;
VAL_ 2298415350 WATT_pMotor_Power_Cutback_Status 1 "Active" 0 "Inactive" ;
VAL_ 2298415350 WATT_pI_DC_Cutback_Status 1 "Active" 0 "Inactive" ;
VAL_ 2298415350 WATT_pController_Therm_Cutback 1 "Active" 0 "Inactive" ;
VAL_ 2298415095 WATT_pPerformance_State 15 "Not Available" 14 "Reserved" 13 "Reserved" 12 "Reserved" 11 "Reserved" 10 "Reserved" 9 "Reserved" 8 "Reserved" 7 "Reserved" 6 "Fault Reaction" 5 "Fault Off" 4 "Enabled" 3 "Energized" 2 "Precharge" 1 "Shutdown" 0 "Initialize" ;
VAL_ 2298415351 WATT_pSpeed_Lim_Cutback_Status 1 "Active" 0 "Inactive" ;
VAL_ 2298415351 WATT_pMotor_Therm_Cutback 1 "Active" 0 "Inactive" ;
VAL_ 2298415351 WATT_pMotor_Power_Cutback_Status 1 "Active" 0 "Inactive" ;
VAL_ 2298415351 WATT_pI_DC_Cutback_Status 1 "Active" 0 "Inactive" ;
VAL_ 2298415351 WATT_pController_Therm_Cutback 1 "Active" 0 "Inactive" ;
VAL_ 2298415090 WATT_pPerformance_State 15 "Not Available" 14 "Reserved" 13 "Reserved" 12 "Reserved" 11 "Reserved" 10 "Reserved" 9 "Reserved" 8 "Reserved" 7 "Reserved" 6 "Fault Reaction" 5 "Fault Off" 4 "Enabled" 3 "Energized" 2 "Precharge" 1 "Shutdown" 0 "Initialize" ;
VAL_ 2298415346 WATT_pSpeed_Lim_Cutback_Status 1 "Active" 0 "Inactive" ;
VAL_ 2298415346 WATT_pMotor_Therm_Cutback 1 "Active" 0 "Inactive" ;
VAL_ 2298415346 WATT_pMotor_Power_Cutback_Status 1 "Active" 0 "Inactive" ;
VAL_ 2298415346 WATT_pI_DC_Cutback_Status 1 "Active" 0 "Inactive" ;
VAL_ 2298415346 WATT_pController_Therm_Cutback 1 "Active" 0 "Inactive" ;
VAL_ 2298415089 WATT_pPerformance_State 15 "Not Available" 14 "Reserved" 13 "Reserved" 12 "Reserved" 11 "Reserved" 10 "Reserved" 9 "Reserved" 8 "Reserved" 7 "Reserved" 6 "Fault Reaction" 5 "Fault Off" 4 "Enabled" 3 "Energized" 2 "Precharge" 1 "Shutdown" 0 "Initialize" ;
VAL_ 2298415345 WATT_pSpeed_Lim_Cutback_Status 1 "Active" 0 "Inactive" ;
VAL_ 2298415345 WATT_pMotor_Therm_Cutback 1 "Active" 0 "Inactive" ;
VAL_ 2298415345 WATT_pMotor_Power_Cutback_Status 1 "Active" 0 "Inactive" ;
VAL_ 2298415345 WATT_pI_DC_Cutback_Status 1 "Active" 0 "Inactive" ;
VAL_ 2298415345 WATT_pController_Therm_Cutback 1 "Active" 0 "Inactive" ;
VAL_ 2298415087 WATT_pPerformance_State 15 "Not Available" 14 "Reserved" 13 "Reserved" 12 "Reserved" 11 "Reserved" 10 "Reserved" 9 "Reserved" 8 "Reserved" 7 "Reserved" 6 "Fault Reaction" 5 "Fault Off" 4 "Enabled" 3 "Energized" 2 "Precharge" 1 "Shutdown" 0 "Initialize" ;
VAL_ 2298415343 WATT_pController_Therm_Cutback 1 "Active" 0 "Inactive" ;
VAL_ 2298415343 WATT_pSpeed_Lim_Cutback_Status 1 "Active" 0 "Inactive" ;
VAL_ 2298415343 WATT_pMotor_Therm_Cutback 1 "Active" 0 "Inactive" ;
VAL_ 2298415343 WATT_pMotor_Power_Cutback_Status 1 "Active" 0 "Inactive" ;
VAL_ 2298415343 WATT_pI_DC_Cutback_Status 1 "Active" 0 "Inactive" ;
VAL_ 2365525248 WATT_pBMC4_Cmd 63 "Not Available" 32 "New Battery Reset" 5 "Set Date" 4 "Set Time" 3 "Iaux Calibration" 2 "Ilower Calibration" 1 "Vlower Calibration" 0 "Vpack Calibration" ;
VAL_ 2365525248 WATT_pBMC_4_Shutdown 3 "Not Available" 2 "Reserved" 1 "Shutdown" 0 "Reserved" ;
VAL_ 2365524992 WATT_pBMC3_Cmd 63 "Not Available" 32 "New Battery Reset" 5 "Set Date" 4 "Set Time" 3 "Iaux Calibration" 2 "Ilower Calibration" 1 "Vlower Calibration" 0 "Vpack Calibration" ;
VAL_ 2365524992 WATT_pBMC_3_Shutdown 3 "Not Available" 2 "Reserved" 1 "Shutdown" 0 "Reserved" ;
VAL_ 2365524736 WATT_pBMC2_Cmd 63 "Not Available" 32 "New Battery Reset" 5 "Set Date" 4 "Set Time" 3 "Iaux Calibration" 2 "Ilower Calibration" 1 "Vlower Calibration" 0 "Vpack Calibration" ;
VAL_ 2365524736 WATT_pBMC_2_Shutdown 3 "Not Available" 2 "Reserved" 1 "Shutdown" 0 "Reserved" ;
VAL_ 2365524480 WATT_pBMC1_Cmd 63 "Not Available" 32 "New Battery Reset" 5 "Set Date" 4 "Set Time" 3 "Iaux Calibration" 2 "Ilower Calibration" 1 "Vlower Calibration" 0 "Vpack Calibration" ;
VAL_ 2365524480 WATT_pBMC_1_Shutdown 3 "Not Available" 2 "Reserved" 1 "Shutdown" 0 "Reserved" ;
VAL_ 2231305728 WATT_pAPU_4_cntrl 15 "No change in state" 14 "Reserved" 13 "Reserved" 12 "Reserved" 11 "Reserved for Active Discharge" 10 "Reserved for Control Vbat" 9 "Speed" 8 "Torque" 7 "Reserved" 6 "Reserved" 5 "Fault Reset" 4 "Reserved for End Active Short" 3 "Reserved for Active Short" 2 "Enable" 1 "Energize" 0 "Shutdown" ;
VAL_ 2231305472 WATT_pAPU_3_cntrl 15 "No change in state" 14 "Reserved" 13 "Reserved" 12 "Reserved" 11 "Reserved for Active Discharge" 10 "Reserved for Control Vbat" 9 "Speed" 8 "Torque" 7 "Reserved" 6 "Reserved" 5 "Fault Reset" 4 "Reserved for End Active Short" 3 "Reserved for Active Short" 2 "Enable" 1 "Energize" 0 "Shutdown" ;
VAL_ 2231305216 WATT_pAPU_2_cntrl 15 "No change in state" 14 "Reserved" 13 "Reserved" 12 "Reserved" 11 "Reserved for Active Discharge" 10 "Reserved for Control Vbat" 9 "Speed" 8 "Torque" 7 "Reserved" 6 "Reserved" 5 "Fault Reset" 4 "Reserved for End Active Short" 3 "Reserved for Active Short" 2 "Enable" 1 "Energize" 0 "Shutdown" ;
VAL_ 2231304960 WATT_pAPU_1_cntrl 15 "No change in state" 14 "Reserved" 13 "Reserved" 12 "Reserved" 11 "Reserved for Active Discharge" 10 "Reserved for Control Vbat" 9 "Speed" 8 "Torque" 7 "Reserved" 6 "Reserved" 5 "Fault Reset" 4 "Reserved for End Active Short" 3 "Reserved for Active Short" 2 "Enable" 1 "Energize" 0 "Shutdown" ;
VAL_ 2231304704 WATT_pEPCU_4_cntrl 15 "No change in state" 14 "Reserved" 13 "Reserved" 12 "Reserved" 11 "Reserved for Active Discharge" 10 "Reserved for Control Vbat" 9 "Speed" 8 "Torque" 7 "Reserved" 6 "Reserved" 5 "Fault Reset" 4 "Reserved for End Active Short" 3 "Reserved for Active Short" 2 "Enable" 1 "Energize" 0 "Shutdown" ;
VAL_ 2231304448 WATT_pEPCU_3_cntrl 15 "No change in state" 14 "Reserved" 13 "Reserved" 12 "Reserved" 11 "Reserved for Active Discharge" 10 "Reserved for Control Vbat" 9 "Speed" 8 "Torque" 7 "Reserved" 6 "Reserved" 5 "Fault Reset" 4 "Reserved for End Active Short" 3 "Reserved for Active Short" 2 "Enable" 1 "Energize" 0 "Shutdown" ;
VAL_ 2231304192 pEPCU_2_Cntrl_Mode 15 "No change in state" 14 "Reserved" 13 "Reserved" 12 "Reserved" 11 "Reserved for Active Discharge" 10 "Reserved for Control Vbat" 9 "Speed" 8 "Torque" 7 "Reserved" 6 "Reserved" 5 "Fault Reset" 4 "Reserved for End Active Short" 3 "Reserved for Active Short" 2 "Enable" 1 "Energize" 0 "Shutdown" ;
VAL_ 2231309056 pEPCU_1_CNTRL_MODE 15 "No change in state" 14 "Reserved" 13 "Reserved" 12 "Reserved" 11 "Reserved for Active Discharge" 10 "Reserved for Control Vbat" 9 "Speed" 8 "Torque" 7 "Reserved" 6 "Reserved" 5 "Fault Reset" 4 "Reserved for End Active Short" 3 "Reserved for Active Short" 2 "Enable" 1 "Energize" 0 "Shutdown" ;
